VERSION ""

NS_ :

BS_:

BU_: PDCF VDC821 VDC397 HAD3971 PDCM CSC PDCR

BO_ 169 RBU_1: 32 PDCF
 SG_ Checksum_RBU_1 : 0|8@1+ (1,0) [0|255] ""  HAD3971
 SG_ RBU_WheelSpeed_FL : 8|15@1+ (0.01,0) [0|327.67] "km/h"  HAD3971
 SG_ RBU_WheelSpeed_FR : 24|15@1+ (0.01,0) [0|327.67] "km/h"  HAD3971
 SG_ RBU_WheelSpeed_RL : 40|15@1+ (0.01,0) [0|327.67] "km/h"  HAD3971
 SG_ RBU_WheelSpeed_RR : 56|15@1+ (0.01,0) [0|327.67] "km/h"  HAD3971
 SG_ RBU_ErrorSt_SBS : 72|1@1+ (1,0) [0|1] ""  HAD3971
 SG_ RBU_Intervention_SBS : 73|1@1+ (1,0) [0|1] ""  HAD3971
 SG_ RBU_EPBAvailableSt_L3 : 74|1@1+ (1,0) [0|1] ""  HAD3971
 SG_ RBU_UsedChannel_L3 : 75|2@1+ (1,0) [0|3] ""  HAD3971
 SG_ RBU_ControllerReleaseSt_L3 : 77|1@1+ (1,0) [0|1] ""  HAD3971
 SG_ RBU_SuspendStatusByDriver_L3 : 78|2@1+ (1,0) [0|3] ""  HAD3971
 SG_ RBU_BrakePedalStatus_Q : 80|2@1+ (1,0) [0|3] ""  HAD3971
 SG_ RBU_BrakePedalStatus : 82|2@1+ (1,0) [0|3] ""  HAD3971
 SG_ RBU_VLCSt : 84|2@1+ (1,0) [0|3] ""  HAD3971
 SG_ RBU_VMC_Error_L3 : 88|3@1+ (1,0) [0|7] ""  HAD3971
 SG_ RBU_DrivingDirection : 91|2@1+ (1,0) [0|3] ""  HAD3971
 SG_ RBU_VehicleSpeed : 96|15@1+ (0.01,0) [0|327.67] "km/h"  HAD3971
 SG_ RBU_TargetGearReq_VMC_1 : 114|3@1+ (1,0) [0|7] ""  HAD3971
 SG_ RBU_TargetGearReqEnable_VMC_1 : 117|1@1+ (1,0) [0|1] ""  HAD3971
 SG_ RBU_VehicleStandstillSt : 118|1@1+ (1,0) [0|1] ""  HAD3971
 SG_ RBU_BrakeLightCtrlCmd : 119|1@1+ (1,0) [0|1] ""  HAD3971
 SG_ RBUIBC_DriveMain2BackupState : 120|4@1+ (1,0) [0|15] "" Vector__XXX
 SG_ RBUIBC_StopMain2BackupState : 124|4@1+ (1,0) [0|7] "" Vector__XXX
 SG_ RBUIPB_RBUSelfTestInfo : 128|4@1+ (1,0) [0|15] "" Vector__XXX
 SG_ RBUIBC_VariantInfo : 132|1@1+ (1,0) [0|1] "" Vector__XXX
 SG_ LiveCounter_RBU_1 : 252|4@1+ (1,0) [0|15] ""  HAD3971

BO_ 1382 RBU_SlaveFVReq: 8 PDCF
 SG_ SECOC_FVReqCode_RBU : 0|8@1+ (1,0) [0|0] ""  VDC397

BO_ 190 RVA_1: 16 PDCF
 SG_ Checksum_RVA_1 : 0|8@1+ (1,0) [0|255] ""  VDC397,HAD3971
 SG_ SteerRearControlAngleReq_RVA : 8|12@1+ (0.01,-20.48) [-20.48|20.47] "°„"  VDC397,HAD3971
 SG_ SteerRearControlSt_RVA : 20|2@1+ (1,0) [0|3] ""  VDC397,HAD3971
 SG_ WorkingSt_RVA : 24|3@1+ (1,0) [0|7] ""  VDC397,HAD3971
 SG_ BehaviorMode_RVA : 27|3@1+ (1,0) [0|7] ""  VDC397,HAD3971
 SG_ ErrorSt_RVA : 30|2@1+ (1,0) [0|3] ""  VDC397,HAD3971
 SG_ IBCControlAvailable_RVA : 32|1@1+ (1,0) [0|1] ""  VDC397,HAD3971
 SG_ APAControlSt_RVA : 33|1@1+ (1,0) [0|1] ""  VDC397,HAD3971
 SG_ APAAbortFeedback_RVA : 34|5@1+ (1,0) [0|31] ""  VDC397,HAD3971
 SG_ SACCControlSt_RVA : 40|2@1+ (1,0) [0|3] ""  VDC397,HAD3971
 SG_ LKAControlSt_RVA : 42|2@1+ (1,0) [0|3] ""  VDC397,HAD3971
 SG_ NOPControlSt_RVA : 44|2@1+ (1,0) [0|3] ""  VDC397,HAD3971
 SG_ Livecounter_RVA_1 : 60|4@1+ (1,0) [0|15] ""  VDC397,HAD3971
 SG_ SECOC_FV_RVA_1 : 64|16@1+ (1,0) [0|0] ""  VDC397
 SG_ SECOC_TMAC_RVA_1 : 80|48@1+ (1,0) [0|0] ""  VDC397

BO_ 188 RWS_1: 16 PDCF
 SG_ Checksum_RWS_1 : 0|8@1+ (1,0) [0|255] ""  HAD3971
 SG_ RearWheelAngle : 8|12@1+ (0.01,-20.48) [-20.48|20.47] "°„"  HAD3971
 SG_ RearWheelAngle_QF : 22|2@1+ (1,0) [0|3] ""  HAD3971
 SG_ RearWheelAngleSpeed : 24|13@1+ (0.01,-40.96) [-40.96|40.95] "°„/s"  HAD3971
 SG_ WorkingSt_RWS : 40|3@1+ (1,0) [0|7] ""  HAD3971
 SG_ ErrorSt_RWS : 43|2@1+ (1,0) [0|3] ""  HAD3971
 SG_ LiveCounter_RWS_1 : 60|4@1+ (1,0) [0|15] ""  HAD3971
 SG_ SECOC_FV_RWS_1 : 64|16@1+ (1,0) [0|0] ""  VDC397
 SG_ SECOC_TMAC_RWS_1 : 80|48@1+ (1,0) [0|0] ""  VDC397

BO_ 189 RWS_2: 8 PDCF
 SG_ MaxAngle_RWS : 8|12@1+ (0.01,-20.48) [-20.48|20.47] "°„"  HAD3971
 SG_ MaxAngleGrad_RWS : 24|13@1+ (0.01,-40.96) [-40.96|40.95] "°„/s"  HAD3971

BO_ 1383 RWS_SlaveFVReq: 8 PDCF
 SG_ SECOC_FVReqCode_RWS : 0|8@1+ (1,0) [0|0] ""  VDC397

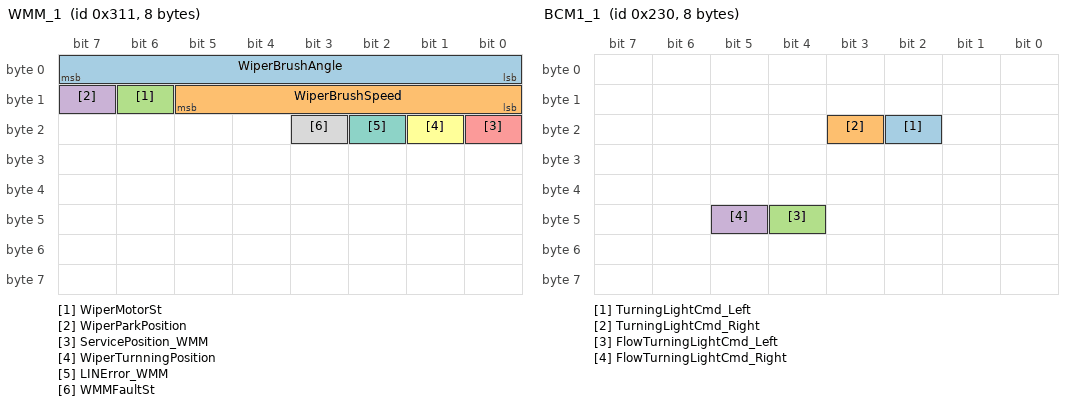
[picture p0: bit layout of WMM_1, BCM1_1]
BO_ 785 WMM_1: 8 PDCF
 SG_ WiperBrushAngle : 0|8@1+ (1,0) [0|255] "degree"  VDC821
 SG_ WiperBrushSpeed : 8|6@1+ (1,0) [0|63] "times/min"  VDC821
 SG_ WiperMotorSt : 14|1@1+ (1,0) [0|1] ""  VDC821
 SG_ WiperParkPosition : 15|1@1+ (1,0) [0|1] ""  VDC821
 SG_ ServicePosition_WMM : 16|1@1+ (1,0) [0|1] ""  VDC821
 SG_ WiperTurnningPosition : 17|1@1+ (1,0) [0|1] ""  VDC821
 SG_ LINError_WMM : 18|1@1+ (1,0) [0|1] ""  VDC821
 SG_ WMMFaultSt : 19|1@1+ (1,0) [0|1] ""  VDC821

BO_ 560 BCM1_1: 8 VDC821
 SG_ TurningLightCmd_Left : 18|1@1+ (1,0) [0|1] ""  PDCF
 SG_ TurningLightCmd_Right : 19|1@1+ (1,0) [0|1] ""  PDCF
 SG_ FlowTurningLightCmd_Left : 44|1@1+ (1,0) [0|1] ""  PDCF
 SG_ FlowTurningLightCmd_Right : 45|1@1+ (1,0) [0|1] ""  PDCF

BO_ 562 BCM1_2: 8 VDC821
 SG_ PowerMode : 4|4@1+ (1,0) [0|15] ""  PDCF

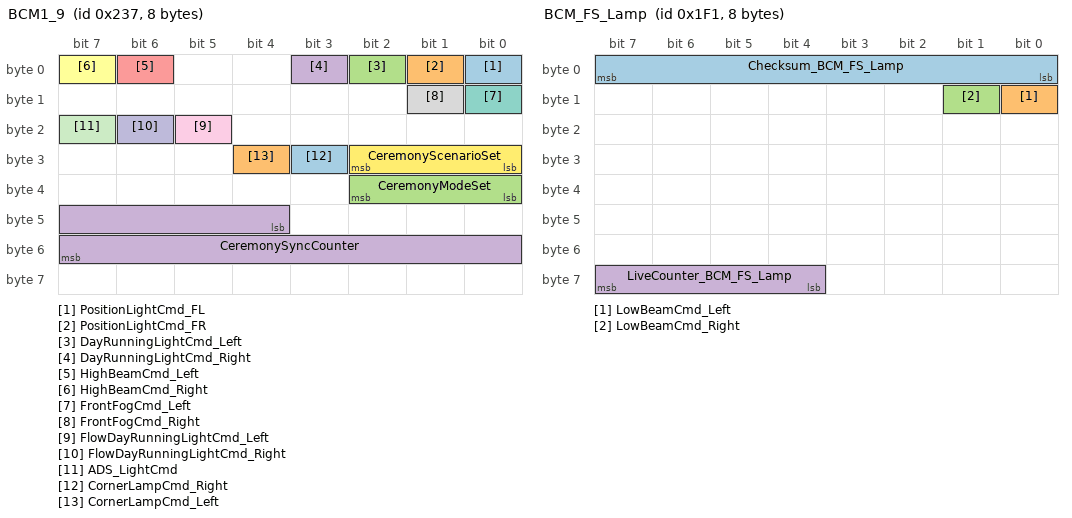
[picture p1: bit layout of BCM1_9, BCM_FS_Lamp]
BO_ 567 BCM1_9: 8 VDC821
 SG_ PositionLightCmd_FL : 0|1@1+ (1,0) [0|1] ""  PDCF
 SG_ PositionLightCmd_FR : 1|1@1+ (1,0) [0|1] ""  PDCF
 SG_ DayRunningLightCmd_Left : 2|1@1+ (1,0) [0|1] ""  PDCF
 SG_ DayRunningLightCmd_Right : 3|1@1+ (1,0) [0|1] ""  PDCF
 SG_ HighBeamCmd_Left : 6|1@1+ (1,0) [0|1] ""  PDCF
 SG_ HighBeamCmd_Right : 7|1@1+ (1,0) [0|1] ""  PDCF
 SG_ FrontFogCmd_Left : 8|1@1+ (1,0) [0|1] ""  PDCF
 SG_ FrontFogCmd_Right : 9|1@1+ (1,0) [0|1] ""  PDCF
 SG_ FlowDayRunningLightCmd_Left : 21|1@1+ (1,0) [0|1] ""  PDCF
 SG_ FlowDayRunningLightCmd_Right : 22|1@1+ (1,0) [0|1] ""  PDCF
 SG_ ADS_LightCmd : 23|1@1+ (1,0) [0|1] ""  PDCF
 SG_ CeremonyScenarioSet : 24|3@1+ (1,0) [0|7] ""  PDCF
 SG_ CornerLampCmd_Right : 27|1@1+ (1,0) [0|1] ""  PDCF
 SG_ CornerLampCmd_Left : 28|1@1+ (1,0) [0|1] ""  PDCF
 SG_ CeremonyModeSet : 32|3@1+ (1,0) [0|7] ""  PDCF
 SG_ CeremonySyncCounter : 44|12@1+ (1,0) [0|4000] ""  PDCF

BO_ 497 BCM_FS_Lamp: 8 VDC821
 SG_ Checksum_BCM_FS_Lamp : 0|8@1+ (1,0) [0|255] ""  PDCF
 SG_ LowBeamCmd_Left : 8|1@1+ (1,0) [0|1] ""  PDCF
 SG_ LowBeamCmd_Right : 9|1@1+ (1,0) [0|1] ""  PDCF
 SG_ LiveCounter_BCM_FS_Lamp : 60|4@1+ (1,0) [0|15] "pulse"  PDCF

BO_ 532 DMS_1: 8 VDC821
 SG_ DMS_ESCModeChangeCmd : 16|4@1+ (1,0) [0|15] ""  PDCF
 SG_ DMS_EPSModeChangeCmd : 20|2@1+ (1,0) [0|3] ""  PDCF

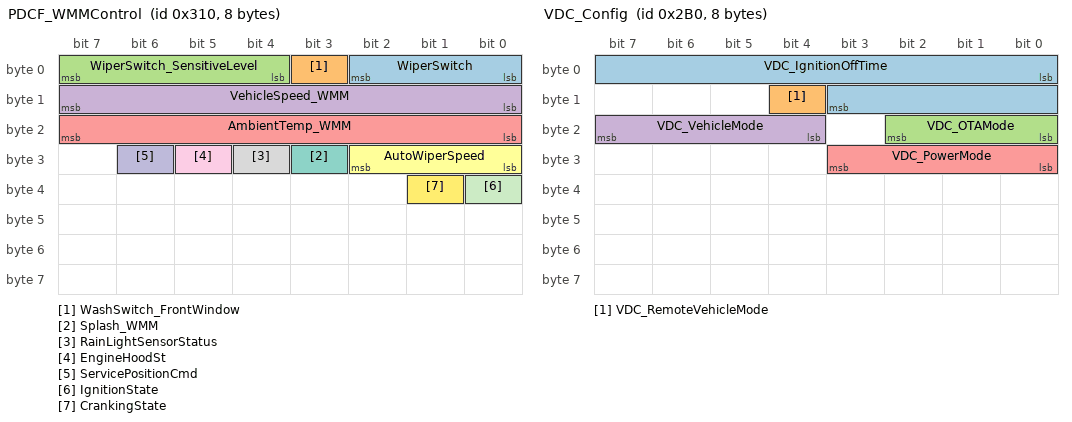
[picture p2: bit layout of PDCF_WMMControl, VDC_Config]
BO_ 784 PDCF_WMMControl: 8 VDC821
 SG_ WiperSwitch : 0|3@1+ (1,0) [0|7] ""  PDCF
 SG_ WashSwitch_FrontWindow : 3|1@1+ (1,0) [0|1] ""  PDCF
 SG_ WiperSwitch_SensitiveLevel : 4|4@1+ (1,0) [0|15] ""  PDCF
 SG_ VehicleSpeed_WMM : 8|8@1+ (2.56,0) [0|652.8] "km/h"  PDCF
 SG_ AmbientTemp_WMM : 16|8@1+ (0.5,-40) [-40|87.5] "°„C"  PDCF
 SG_ AutoWiperSpeed : 24|3@1+ (1,0) [0|7] ""  PDCF
 SG_ Splash_WMM : 27|1@1+ (1,0) [0|1] ""  PDCF
 SG_ RainLightSensorStatus : 28|1@1+ (1,0) [0|1] ""  PDCF
 SG_ EngineHoodSt : 29|1@1+ (1,0) [0|1] ""  PDCF
 SG_ ServicePositionCmd : 30|1@1+ (1,0) [0|1] ""  PDCF
 SG_ IgnitionState : 32|1@1+ (1,0) [0|1] ""  PDCF
 SG_ CrankingState : 33|1@1+ (1,0) [0|1] ""  PDCF

BO_ 890 SignLampCmd_1: 8 VDC821
 SG_ SignLamp1_Cmd : 12|1@1+ (1,0) [0|1] ""  PDCF
 SG_ SignLamp2_Cmd : 13|1@1+ (1,0) [0|1] ""  PDCF

BO_ 688 VDC_Config: 8 VDC821
 SG_ VDC_IgnitionOffTime : 0|12@1+ (1,0) [0|4095] "minute"  PDCF
 SG_ VDC_RemoteVehicleMode : 12|1@1+ (1,0) [0|1] ""  PDCF
 SG_ VDC_OTAMode : 16|3@1+ (1,0) [0|7] ""  PDCF
 SG_ VDC_VehicleMode : 20|4@1+ (1,0) [0|15] ""  PDCF
 SG_ VDC_PowerMode : 24|4@1+ (1,0) [0|15] ""  PDCF

BO_ 256 ADV_2: 32 VDC397
 SG_ Checksum_ADV_2 : 0|8@1+ (1,0) [0|255] ""  PDCF
 SG_ ADV_ErrorSt_EPS : 8|1@1+ (1,0) [0|1] ""  PDCF
 SG_ ADV_AutoParkingModeReq : 9|3@1+ (1,0) [0|7] ""  PDCF
 SG_ ADV_AutoParkingRequestSt : 12|2@1+ (1,0) [0|3] ""  PDCF
 SG_ APA_DriverInterventionSt : 15|1@1+ (1,0) [0|1] ""  PDCF
 SG_ ADV_ErrorSt_APA : 16|2@1+ (1,0) [0|3] ""  PDCF
 SG_ ADV_ErrorSt_RPA : 18|2@1+ (1,0) [0|3] ""  PDCF
 SG_ ADV_ErrorSt_AVP : 20|2@1+ (1,0) [0|3] ""  PDCF
 SG_ ADV_ErrorSt_RVA : 22|2@1+ (1,0) [0|3] ""  PDCF
 SG_ ADV_WorkingSt_APA : 24|3@1+ (1,0) [0|7] ""  PDCF
 SG_ ADV_WorkingSt_RPA : 27|3@1+ (1,0) [0|7] ""  PDCF
 SG_ ADV_WorkingSt_AVP : 32|3@1+ (1,0) [0|7] ""  PDCF
 SG_ APA_SecureRequest : 35|1@1+ (1,0) [0|1] ""  PDCF
 SG_ APA_AutoParkingReq : 36|1@1+ (1,0) [0|1] ""  PDCF
 SG_ APA_DirectionCmd : 37|2@1+ (1,0) [0|3] ""  PDCF
 SG_ ADV_SteeringWheelAngleRequest : 40|15@1+ (0.04375,0) [0|1433.55625] "°„"  PDCF
 SG_ ADV_SteeringWheelAngleSignReques : 56|2@1+ (1,0) [0|3] ""  PDCF
 SG_ ADV_SteeringWheelAngleControlReq : 58|2@1+ (1,0) [0|3] ""  PDCF
 SG_ ADV_RearWheelAngleRequestSt : 62|2@1+ (1,0) [0|3] ""  PDCF
 SG_ ADV_RearWheelAngleRequest : 64|12@1+ (0.01,-20.48) [-20.48|20.47] "°„"  PDCF
 SG_ APA_BrakeFunctionMode : 76|4@1+ (1,0) [0|15] ""  PDCF
 SG_ APA_StopDistance : 80|12@1+ (1,0) [0|4095] "cm"  PDCF
 SG_ APA_SpeedLimitation : 96|8@1+ (0.1,0) [0|15] "km/h"  PDCF
 SG_ APA_FailureBrakeMode : 104|3@1+ (1,0) [0|7] ""  PDCF
 SG_ APA_EPBLockedRequest : 107|1@1+ (1,0) [0|1] ""  PDCF
 SG_ APA_EPBRequestEnable : 108|1@1+ (1,0) [0|1] ""  PDCF
 SG_ LiveCounter_ADV_2 : 188|4@1+ (1,0) [0|15] "Pulse"  PDCF
 SG_ SECOC_FV_ADV_2 : 192|16@1+ (1,0) [0|0] ""  PDCF
 SG_ SECOC_TMAC_ADV_2 : 208|48@1+ (1,0) [0|0] ""  PDCF

BO_ 151 HCU_2_10: 32 VDC397
 SG_ Checksum_HCU_2_10 : 0|8@1+ (1,0) [0|255] ""  PDCF
 SG_ HCU_MCU1TMSpeed : 8|16@1+ (1,-30000) [-30000|30000] "rpm"  PDCF
 SG_ HCU_FrontWheelActTorque : 24|14@1+ (1,-8000) [-8000|8000] "Nm"  PDCF
 SG_ HCU_FrontWheelActTorqueSt : 39|1@1+ (1,0) [0|1] ""  PDCF
 SG_ HCU_FrontWheelMaxDriveTorque : 40|13@1+ (1,0) [0|8000] "Nm"  PDCF
 SG_ HCU_FrontWheelMaxDriveTorqueSt : 55|1@1+ (1,0) [0|1] ""  PDCF
 SG_ HCU_FrontWheelMaxBrakeRegTorque : 56|13@1+ (1,-8000) [-8000|0] "Nm"  PDCF
 SG_ HCU_FrontWheelMaxBrakeRegTorqSt : 71|1@1+ (1,0) [0|1] ""  PDCF
 SG_ HCU_FrontWheelBrakeRegTorque : 72|13@1+ (1,-8000) [-8000|0] "Nm"  PDCF
 SG_ HCU_FrontWheelBrakeRegTorqueSt : 87|1@1+ (1,0) [0|1] ""  PDCF
 SG_ HCU_MCU2TMSpeed : 88|16@1+ (1,-30000) [-30000|30000] "rpm"  PDCF
 SG_ HCU_RearWheelActTorque : 104|14@1+ (1,-8000) [-8000|8000] "Nm"  PDCF
 SG_ HCU_RearWheelActTorqueSt : 119|1@1+ (1,0) [0|1] ""  PDCF
 SG_ HCU_RearWheelMaxDriveTorque : 120|13@1+ (1,0) [0|8000] "Nm"  PDCF
 SG_ HCU_RearWheelMaxDriveTorqueSt : 135|1@1+ (1,0) [0|1] ""  PDCF
 SG_ HCU_RearWheelMaxBrakeRegTorque : 136|13@1+ (1,-8000) [-8000|0] "Nm"  PDCF
 SG_ HCU_RearWheelMaxBrakeRegTorqSt : 151|1@1+ (1,0) [0|1] ""  PDCF
 SG_ HCU_RearWheelBrakeRegTorque : 152|13@1+ (1,-8000) [-8000|0] "Nm"  PDCF
 SG_ HCU_RearWheelBrakeRegTorqueSt : 167|1@1+ (1,0) [0|1] ""  PDCF
 SG_ LiveCounter_HCU_2_10 : 252|4@1+ (1,0) [0|15] "Pulse"  PDCF

BO_ 290 HCU_2_12: 16 VDC397
 SG_ Checksum_HCU_2_12 : 0|8@1+ (1,0) [0|255] ""  PDCF
 SG_ HCU2_LeverInfo : 8|3@1+ (1,0) [0|7] ""  PDCF
 SG_ HCU_HighVoltageStatus : 11|1@1+ (1,0) [0|1] ""  PDCF
 SG_ HCU_AutoParkingResponse_HPA : 30|1@1+ (1,0) [0|1] ""  PDCF
 SG_ HCU_AutoParkingResponse_AVP : 31|1@1+ (1,0) [0|1] ""  PDCF
 SG_ HCU_AutoParkingResponse_APA : 32|1@1+ (1,0) [0|1] ""  PDCF
 SG_ HCU_AutoParkingResponse_RPA : 33|1@1+ (1,0) [0|1] ""  PDCF
 SG_ HCU_CapabilitySt_AutoParking : 34|2@1+ (1,0) [0|3] ""  PDCF
 SG_ HCU_PowertrainErrorSt : 40|1@1+ (1,0) [0|1] ""  PDCF
 SG_ HCU_PowertrainWorkSt : 41|3@1+ (1,0) [0|7] ""  PDCF
 SG_ HCU_MCU1TorqueCtrlAvailableSt : 44|1@1+ (1,0) [0|1] ""  PDCF
 SG_ HCU_MCU2TorqueCtrlAvailableSt : 46|1@1+ (1,0) [0|1] ""  PDCF
 SG_ Livecounter_HCU_2_12 : 60|4@1+ (1,0) [0|15] "pulse"  PDCF

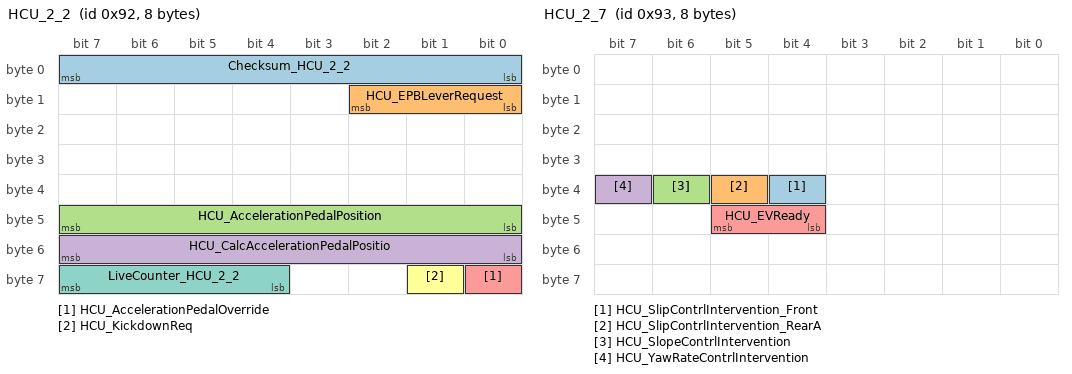
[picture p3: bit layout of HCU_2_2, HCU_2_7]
BO_ 146 HCU_2_2: 8 VDC397
 SG_ Checksum_HCU_2_2 : 0|8@1+ (1,0) [0|255] ""  PDCF
 SG_ HCU_EPBLeverRequest : 8|3@1+ (1,0) [0|7] ""  PDCF
 SG_ HCU_AccelerationPedalPosition : 40|8@1+ (0.4,0) [0|100] "%"  PDCF
 SG_ HCU_CalcAccelerationPedalPositio : 48|8@1+ (0.4,0) [0|100] "%"  PDCF
 SG_ HCU_AccelerationPedalOverride : 56|1@1+ (1,0) [0|1] ""  PDCF
 SG_ HCU_KickdownReq : 57|1@1+ (1,0) [0|1] ""  PDCF
 SG_ LiveCounter_HCU_2_2 : 60|4@1+ (1,0) [0|15] ""  PDCF

BO_ 264 HCU_2_4: 24 VDC397
 SG_ Checksum_HCU_2_4 : 0|8@1+ (1,0) [0|255] ""  PDCF
 SG_ HCU_DriverTorq_FrontWheel : 8|16@1+ (1,-3000) [-3000|13000] "Nm"  PDCF
 SG_ HCU_AutoDrivingResponseSt_L12 : 24|1@1+ (1,0) [0|1] ""  PDCF
 SG_ HCU_AutoDrivingResponseSt_L3 : 25|1@1+ (1,0) [0|1] ""  PDCF
 SG_ HCU_CruiseControlSt : 26|2@1+ (1,0) [0|3] ""  PDCF
 SG_ HCU_CapabilitySt_AutoDriving : 28|2@1+ (1,0) [0|3] ""  PDCF
 SG_ HCU_DriverTorq_RearWheel : 32|16@1+ (1,-3000) [-3000|13000] "Nm"  PDCF
 SG_ HCU_GradientAccelerationPedal : 48|8@1+ (2,-253) [-253|257] "%/s"  PDCF
 SG_ LiveCounter_HCU_2_4 : 124|4@1+ (1,0) [0|15] ""  PDCF

BO_ 147 HCU_2_7: 8 VDC397
 SG_ HCU_SlipContrlIntervention_Front : 36|1@1+ (1,0) [0|1] ""  PDCF
 SG_ HCU_SlipContrlIntervention_RearA : 37|1@1+ (1,0) [0|1] ""  PDCF
 SG_ HCU_SlopeContrlIntervention : 38|1@1+ (1,0) [0|1] ""  PDCF
 SG_ HCU_YawRateContrlIntervention : 39|1@1+ (1,0) [0|1] ""  PDCF
 SG_ HCU_EVReady : 44|2@1+ (1,0) [0|3] ""  PDCF

BO_ 1376 VDC397_MasterFVM: 16 VDC397
 SG_ SECOC_TripCounter : 0|24@1+ (1,0) [0|0] ""  PDCF
 SG_ SECOC_ResetCounter : 24|16@1+ (1,0) [0|0] ""  PDCF
 SG_ SECOC_Authenticator : 40|88@1+ (1,0) [0|0] ""  PDCF

BO_ 280 VDC_1: 32 VDC397
 SG_ Checksum_VDC_1 : 0|8@1+ (1,0) [0|255] ""  PDCF
 SG_ VDC_AutoDrivingReq_L12 : 8|2@1+ (1,0) [0|3] ""  PDCF
 SG_ VDC_DecelerationReqEnable_AEB : 10|2@1+ (1,0) [0|3] ""  PDCF
 SG_ VDC_SteeringTorqueRequestSign : 12|1@1+ (1,0) [0|1] ""  PDCF
 SG_ VDC_SteeringTorqueReqSt : 13|1@1+ (1,0) [0|1] ""  PDCF
 SG_ VDC_Intervention_LKA : 14|2@1+ (1,0) [0|3] ""  PDCF
 SG_ VDC_WorkingSt_LKA : 16|2@1+ (1,0) [0|3] ""  PDCF
 SG_ VDC_ErrorSt_LKA : 18|1@1+ (1,0) [0|1] ""  PDCF
 SG_ VDC_AccelerationPedalOverride : 19|1@1+ (1,0) [0|1] ""  PDCF
 SG_ VDC_WorkingSt_AEB_L12 : 20|2@1+ (1,0) [0|3] ""  PDCF
 SG_ VDC_ErrorSt_AEB_L12 : 22|1@1+ (1,0) [0|1] ""  PDCF
 SG_ VDC_ErrorSt_ACC_L12 : 23|1@1+ (1,0) [0|1] ""  PDCF
 SG_ VDC_SpeedChangeRequest_L12 : 24|11@1+ (0.01,-10.21) [-10.21|10.21] "m/s2"  PDCF
 SG_ VDC_DriveAwayReq_L12 : 35|1@1+ (1,0) [0|1] ""  PDCF
 SG_ VDC_StopReq_L12 : 36|1@1+ (1,0) [0|1] ""  PDCF
 SG_ VDC_WorkingSt_ACC_L12 : 37|3@1+ (1,0) [0|7] ""  PDCF
 SG_ VDC_TakeOverTip_LCA : 40|1@1+ (1,0) [0|1] ""  PDCF
 SG_ VDC_ABPReq_L12 : 41|1@1+ (1,0) [0|1] ""  PDCF
 SG_ VDC_AWBReq_L12 : 42|1@1+ (1,0) [0|1] ""  PDCF
 SG_ VDC_AWBlevel_L12 : 43|3@1+ (1,0) [0|7] ""  PDCF
 SG_ VDC_CruiseModeFunctionInd : 46|2@1+ (1,0) [0|3] ""  PDCF
 SG_ VDC_BrakeModeReq_L12 : 48|2@1+ (1,0) [0|3] ""  PDCF
 SG_ VDC_DrivedownModeReq_L12 : 50|2@1+ (1,0) [0|3] ""  PDCF
 SG_ VDC_SecureRequest_L12 : 52|1@1+ (1,0) [0|1] ""  PDCF
 SG_ VDC_AEBSensitivity_L12 : 53|2@1+ (1,0) [0|3] ""  PDCF
 SG_ VDC_ErrorSt_LCA : 55|1@1+ (1,0) [0|1] ""  PDCF
 SG_ VDC_AutoDrivingReq : 56|2@1+ (1,0) [0|3] ""  PDCF
 SG_ VDC_AutoDrivingLevel : 58|2@1+ (1,0) [0|3] ""  PDCF
 SG_ VDC_HandsOffTip_LCA : 60|2@1+ (1,0) [0|3] ""  PDCF
 SG_ VDC_ErrorSt_SACC : 62|2@1+ (1,0) [0|3] ""  PDCF
 SG_ VDC_DecelerationReq_AEB : 64|10@1+ (0.01,-10.21) [-10.21|0.2] "m/s2"  PDCF
 SG_ VDC_WorkingSt_LCA : 75|3@1+ (1,0) [0|7] ""  PDCF
 SG_ VDC_ErrorSt_VDC : 79|1@1+ (1,0) [0|1] ""  PDCF
 SG_ VDC_SteeringTorqueRequest : 80|10@1+ (0.01,0) [0|10] "Nm"  PDCF
 SG_ VDC_AutoDrivingModeReq : 90|3@1+ (1,0) [0|7] ""  PDCF
 SG_ VDC_WorkingSt_SACC : 93|3@1+ (1,0) [0|7] ""  PDCF
 SG_ VDC_WorkingSt_DCLC : 96|3@1+ (1,0) [0|7] ""  PDCF
 SG_ VDC_ErrorSt_EMA : 100|1@1+ (1,0) [0|1] ""  PDCF
 SG_ VDC_WorkingSt_EMA : 101|3@1+ (1,0) [0|7] ""  PDCF
 SG_ VDC_SteeringWheelAngleRequest : 104|15@1+ (0.04375,0) [0|1433.55625] "°„"  PDCF
 SG_ SACC_RearWheelAngleRequestSt : 119|1@1+ (1,0) [0|1] ""  PDCF
 SG_ VDC_SteeringWheelAngleSignReques : 120|2@1+ (1,0) [0|3] ""  PDCF
 SG_ VDC_SteeringWheelAngleControlReq : 122|2@1+ (1,0) [0|3] ""  PDCF
 SG_ SACC_RearWheelReturnReq : 124|1@1+ (1,0) [0|1] ""  PDCF
 SG_ LKA_RearWheelAngleRequestSt : 125|1@1+ (1,0) [0|1] ""  PDCF
 SG_ LKA_RearWheelReturnReq : 126|1@1+ (1,0) [0|1] ""  PDCF
 SG_ VDC_AutoDrivingModeReq_EMA : 127|1@1+ (1,0) [0|1] ""  PDCF
 SG_ VDC_SteeringWheelBlendingGain : 128|8@1+ (1,0) [0|100] "%"  PDCF
 SG_ VDC_SteeringMaxTorqueRequest : 136|10@1+ (0.01,0) [0|10.23] "Nm"  PDCF
 SG_ SACC_RearWheelAngleRequest : 152|12@1+ (0.01,-20.48) [-20.48|20.47] "°„"  PDCF
 SG_ LKA_RearWheelAngleRequest : 168|12@1+ (0.01,-20.48) [-20.48|20.47] "°„"  PDCF
 SG_ VDC_WorkingSt_FCW : 180|2@1+ (1,0) [0|3] ""  PDCF
 SG_ VDC_ErrorSt_FCW : 182|1@1+ (1,0) [0|1] ""  PDCF
 SG_ LiveCounter_VDC_1 : 188|4@1+ (1,0) [0|15] ""  PDCF

BO_ 282 HAD_3: 32 HAD3971
 SG_ Checksum_HAD_3 : 0|8@1+ (1,0) [0|255] ""  PDCF
 SG_ HAD_AutoDrivingReq_L3 : 8|2@1+ (1,0) [0|3] ""  PDCF
 SG_ HAD_SpeedChangeRequest_L3 : 10|11@1+ (0.01,-10.21) [-10.21|10.21] "m/s2"  PDCF
 SG_ HAD_TimeGapSetting : 21|3@1+ (1,0) [0|7] ""  PDCF
 SG_ NOP_RearWheelAngleRequest : 24|12@1+ (0.01,-20.48) [-20.48|20.47] "°„"  PDCF
 SG_ NOP_RearWheelAngleRequestSt : 36|1@1+ (1,0) [0|1] ""  PDCF
 SG_ NOP_RearWheelReturnReq : 37|1@1+ (1,0) [0|1] ""  PDCF
 SG_ HAD_ObjectDetection : 38|1@1+ (1,0) [0|1] ""  PDCF
 SG_ HAD_TakeOverReq : 39|1@1+ (1,0) [0|1] ""  PDCF
 SG_ HAD_CruiseSpeedSetting_ACC : 40|8@1+ (1,0) [0|255] "km/h"  PDCF
 SG_ HAD_SysTextinfo : 48|4@1+ (1,0) [0|15] ""  PDCF
 SG_ HAD_LDWModeInd : 52|2@1+ (1,0) [0|3] ""  PDCF
 SG_ HAD_AutoLightModeReq : 54|1@1+ (1,0) [0|1] ""  PDCF
 SG_ HAD_HazardWarningLampRequest : 55|1@1+ (1,0) [0|1] ""  PDCF
 SG_ HAD_WorkingSt_LDW : 56|2@1+ (1,0) [0|3] ""  PDCF
 SG_ HAD_WarningCmd_LDW : 58|2@1+ (1,0) [0|3] ""  PDCF
 SG_ HAD_LDWLaneDetectSt : 64|2@1+ (1,0) [0|3] ""  PDCF
 SG_ HAD_SensitivityInd_LDW : 66|2@1+ (1,0) [0|3] ""  PDCF
 SG_ HAD_ErrorSt_LDW : 68|1@1+ (1,0) [0|1] ""  PDCF
 SG_ HAD_WorkingSt_FCW : 69|2@1+ (1,0) [0|3] ""  PDCF
 SG_ HAD_DriveAwayReq_L3 : 71|1@1+ (1,0) [0|1] ""  PDCF
 SG_ HAD_StopReq_L3 : 72|1@1+ (1,0) [0|1] ""  PDCF
 SG_ HAD_AccelerationPedalOverride : 73|1@1+ (1,0) [0|1] ""  PDCF
 SG_ HAD_SensitivityInd_FCW : 74|2@1+ (1,0) [0|3] ""  PDCF
 SG_ HAD_FCWModeInd : 76|2@1+ (1,0) [0|3] ""  PDCF
 SG_ HAD_WiperAutoLeverReq : 78|1@1+ (1,0) [0|1] ""  PDCF
 SG_ HAD_VASFunctionInd : 79|1@1+ (1,0) [0|1] ""  PDCF
 SG_ HAD_SACCNotSatisfiedCondition : 80|3@1+ (1,0) [0|7] ""  PDCF
 SG_ HAD_LDW_SpeechControlFeedback : 83|3@1+ (1,0) [0|7] ""  PDCF
 SG_ HAD_IFCSystemError : 86|2@1+ (1,0) [0|3] ""  PDCF
 SG_ HAD_IFCCalibrationStatus : 88|2@1+ (1,0) [0|3] ""  PDCF
 SG_ HAD_WarningCmd_VAS : 90|1@1+ (1,0) [0|1] ""  PDCF
 SG_ HAD_LeftTurningLampRequest : 91|2@1+ (1,0) [0|3] ""  PDCF
 SG_ HAD_RightTurningLampRequest : 93|2@1+ (1,0) [0|3] ""  PDCF
 SG_ HAD_ValetModeStatus : 95|1@1+ (1,0) [0|1] ""  PDCF
 SG_ HAD_BrakeModeReq_L3 : 96|2@1+ (1,0) [0|3] ""  PDCF
 SG_ HAD_DrivedownModeReq_L3 : 98|2@1+ (1,0) [0|3] ""  PDCF
 SG_ HAD_SecureRequest_L3 : 100|2@1+ (1,0) [0|3] ""  PDCF
 SG_ HAD_ErrorSt_AutoDriving_L3 : 102|1@1+ (1,0) [0|1] ""  PDCF
 SG_ HAD_WorkingSt_NOP : 104|3@1+ (1,0) [0|7] ""  PDCF
 SG_ HAD_ErrorSt_NOP : 107|2@1+ (1,0) [0|3] ""  PDCF
 SG_ HAD_ErrorSt_HAD : 109|1@1+ (1,0) [0|1] ""  PDCF
 SG_ HAD_AutoDrivingModeReq_NOP : 110|1@1+ (1,0) [0|1] ""  PDCF
 SG_ HAD_AutoDrivingModeReq_NGP : 111|1@1+ (1,0) [0|1] ""  PDCF
 SG_ HAD_SteeringWheelBlendingGain : 112|8@1+ (1,0) [0|100] "%"  PDCF
 SG_ HAD_SteeringWheelAngleRequest : 120|15@1+ (0.04375,0) [0|1433.55625] "°„"  PDCF
 SG_ HAD_SteeringWheelAngleSignReques : 136|2@1+ (1,0) [0|3] ""  PDCF
 SG_ HAD_SteeringWheelAngleControlReq : 138|2@1+ (1,0) [0|3] ""  PDCF
 SG_ HAD_WorkingSt_NGP : 144|3@1+ (1,0) [0|7] ""  PDCF
 SG_ HAD_ErrorSt_NGP : 147|2@1+ (1,0) [0|3] ""  PDCF
 SG_ LiveCounter_HAD_3 : 188|4@1+ (1,0) [0|15] ""  PDCF

BO_ 512 ACU_1: 8 PDCM
 SG_ CrashInfo : 8|1@1+ (1,0) [0|1] ""  PDCF
 SG_ SysSt_ACU : 16|2@1+ (1,0) [0|3] ""  PDCF

BO_ 586 DDCU_1: 8 PDCM
 SG_ DoorSt_FL : 2|1@1+ (1,0) [0|1] ""  PDCF

BO_ 580 DSCU_1: 8 PDCM
 SG_ SeatBeltSt_DSCU : 28|2@1+ (1,0) [0|3] ""  PDCF

BO_ 288 EGSM_1: 8 PDCM
 SG_ EGSM_ParkButton : 8|1@1+ (1,0) [0|1] ""  PDCF

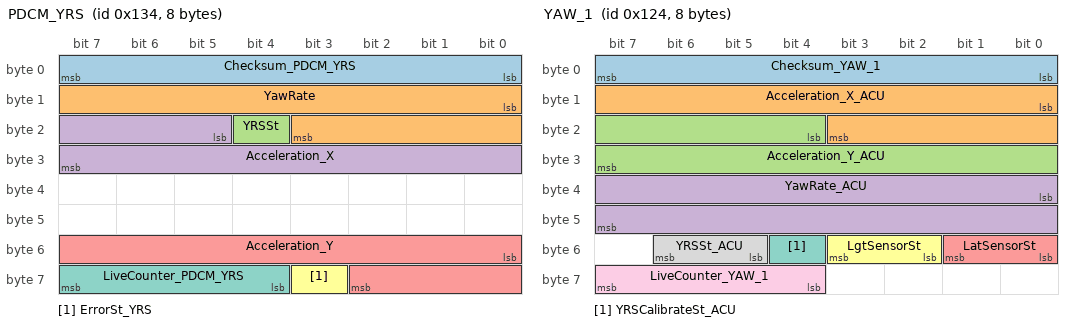
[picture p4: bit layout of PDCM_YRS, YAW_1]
BO_ 308 PDCM_YRS: 8 PDCM
 SG_ Checksum_PDCM_YRS : 0|8@1+ (1,0) [0|255] ""  PDCF
 SG_ YawRate : 8|12@1+ (0.05,-100) [-100|100] "deg/s"  PDCF
 SG_ YRSSt : 20|1@1+ (1,0) [0|1] ""  PDCF
 SG_ Acceleration_X : 21|11@1+ (0.027127,-21.593) [-21.593|21.593184] "m/s2"  PDCF
 SG_ Acceleration_Y : 48|11@1+ (0.027127,-21.593) [-21.593|21.593184] "m/s2"  PDCF
 SG_ ErrorSt_YRS : 59|1@1+ (1,0) [0|1] ""  PDCF
 SG_ LiveCounter_PDCM_YRS : 60|4@1+ (1,0) [0|15] ""  PDCF

BO_ 588 PDCU_1: 8 PDCM
 SG_ DoorSt_FR : 2|1@1+ (1,0) [0|1] ""  PDCF

BO_ 292 YAW_1: 8 PDCM
 SG_ Checksum_YAW_1 : 0|8@1+ (1,0) [0|255] ""  PDCF
 SG_ Acceleration_X_ACU : 8|12@1+ (0.001,-2) [-2|2] "g"  PDCF
 SG_ Acceleration_Y_ACU : 20|12@1+ (0.001,-2) [-2|2] "g"  PDCF
 SG_ YawRate_ACU : 32|16@1+ (0.01,-180) [-180|180] "deg/s"  PDCF
 SG_ LatSensorSt : 48|2@1+ (1,0) [0|3] ""  PDCF
 SG_ LgtSensorSt : 50|2@1+ (1,0) [0|3] ""  PDCF
 SG_ YRSCalibrateSt_ACU : 52|1@1+ (1,0) [0|1] ""  PDCF
 SG_ YRSSt_ACU : 53|2@1+ (1,0) [0|3] ""  PDCF
 SG_ LiveCounter_YAW_1 : 60|4@1+ (1,0) [0|15] ""  PDCF

BO_ 640 HU_1: 8 CSC
 SG_ EPBFunctionSet : 28|2@1+ (1,0) [0|3] ""  PDCF

CM_ SG_ 169 Checksum_RBU_1 "The checksum is used to check whether the data from the CPU buffer are shifted without transmission errors to the CAN communication controller buffer and vice versa.";
CM_ SG_ 169 RBU_WheelSpeed_FL "This signal is front left wheel speed which sent by ABS with filtering. ";
CM_ SG_ 169 RBU_WheelSpeed_FR "This signal is front right wheel speed which sent by ABS with filtering.";
CM_ SG_ 169 RBU_WheelSpeed_RL "This signal is rear left wheel speed which sent by ABS with filtering.";
CM_ SG_ 169 RBU_WheelSpeed_RR "This signal is rear right wheel speed which sent by ABS with filtering.";
CM_ SG_ 169 RBU_ErrorSt_SBS "This signal indicates the SBS function error status.";
CM_ SG_ 169 RBU_Intervention_SBS "The signal indicates if the SBS function is intervention or not.";
CM_ SG_ 169 RBU_EPBAvailableSt_L3 "This signal indicates EPB communication is available or not by RBU";
CM_ SG_ 169 RBU_UsedChannel_L3 "This signal indicates RBU feedback which communication channel is used for L3 control.";
CM_ SG_ 169 RBU_ControllerReleaseSt_L3 "This signal indicates RBU is available for L3 autodriving function or not.Release means RBU is available for L3 Control£¨Notrelease means RBU is not available for L3 Control.";
CM_ SG_ 169 RBU_SuspendStatusByDriver_L3 "This signal indicates if the RBU system is suspend during L3 Function(Driver)";
CM_ SG_ 169 RBU_BrakePedalStatus_Q "This signal is the qualifier of brake pedal status.";
CM_ SG_ 169 RBU_BrakePedalStatus "This signal is the brake pedal status.";
CM_ SG_ 169 RBU_VLCSt "This signal indicates the vehicle longitudinal control status for L123 autodriving function.";
CM_ SG_ 169 RBU_VMC_Error_L3 "This signal indicates RBU system in RBU is available for L3 autodriving function or not.";
CM_ SG_ 169 RBU_DrivingDirection "The signal indicates driving direction of the vehicle.";
CM_ SG_ 169 RBU_VehicleSpeed "The signal describes the raw vehicle speed calculated by ABS. The ABS calculates the vehicle speed based on the raw wheel speed signals from the wheel speed sensors. The vehicle speed output could be the average of the wheel speeds of the driven axle.";
CM_ SG_ 169 RBU_TargetGearReq_VMC_1 "RBU request to change the lever  position.";
CM_ SG_ 169 RBU_TargetGearReqEnable_VMC_1 "This signal is enable flag for gear request of ADAS Control by RBU";
CM_ SG_ 169 RBU_VehicleStandstillSt "The signal indicates the vehicle whether is in standstill or not by RBU";
CM_ SG_ 169 RBU_BrakeLightCtrlCmd "The signal indicates the brake light control command of RBU";
CM_ SG_ 169 RBUIBC_DriveMain2BackupState "State of the backup actuator for automated driving with brake redundancy";
CM_ SG_ 169 RBUIBC_StopMain2BackupState "State of the backup actuator for automated parking with brake redundancy";
CM_ SG_ 169 RBUIPB_RBUSelfTestInfo "IBC RBU coordination info for RBU BAT test";
CM_ SG_ 169 RBUIBC_VariantInfo "Variant Information of RBU";
CM_ SG_ 169 LiveCounter_RBU_1 "The Livecounter is used to check the signal consistency of the messages . If the signals are consecutive, the LiveCounter should also be sequential in the way 0, 1, 2 ...X(depends on E2E usage), 0, 1 °≠";
CM_ SG_ 1382 SECOC_FVReqCode_RBU "FV  request code. The signal shall be procceded following the byte order requirement in FAW-CYS-0033, i.e. SECOC spec";
CM_ SG_ 190 Checksum_RVA_1 "The checksum is used to check whether the data from the CPU buffer are shifted without transmission errors to the CAN communication controller buffer and vice versa.";
CM_ SG_ 190 SteerRearControlAngleReq_RVA "Target angle request from Master Controller";
CM_ SG_ 190 SteerRearControlSt_RVA "Control status for angle request, corporate with steer angle request to realize rear axle angle control";
CM_ SG_ 190 WorkingSt_RVA "This signal indicates the working status of RVA";
CM_ SG_ 190 BehaviorMode_RVA "This signal indicates the behavior mode of RVA";
CM_ SG_ 190 ErrorSt_RVA "This signal indicates the error status of RVA";
CM_ SG_ 190 IBCControlAvailable_RVA "Indicates IBC Control RWS is available or not.";
CM_ SG_ 190 APAControlSt_RVA "Indicates APA Control Request Feedback";
CM_ SG_ 190 APAAbortFeedback_RVA "This signal indicates APA Abort Feedback";
CM_ SG_ 190 SACCControlSt_RVA "This signal indicates the status of SACC Control SteerRearAngle";
CM_ SG_ 190 LKAControlSt_RVA "This signal indicates the status of LKA Control SteerRearAngle";
CM_ SG_ 190 NOPControlSt_RVA "This signal indicates the status of NOP Control SteerRearAngle";
CM_ SG_ 190 Livecounter_RVA_1 "The Livecounter is used to check the signal consistency of the messages . If the signals are consecutive, the LiveCounter should also be sequential in the way 0, 1, 2 °≠X(depends on E2E usage), 0, 1 °≠";
CM_ SG_ 190 SECOC_FV_RVA_1 "Fresh value signal for SECOC. The signal shall be proceeded following the byte order requirement in FAW-CYS-0033, i.e. SECOC spec";
CM_ SG_ 190 SECOC_TMAC_RVA_1 "Truncated MAC signal for SECOC. The signal shall be proceeded following the byte order requirement in FAW-CYS-0033, i.e. SECOC spec";
CM_ SG_ 188 Checksum_RWS_1 "The checksum is used to check whether the data from the CPU buffer are shifted without transmission errors to the CAN communication controller buffer and vice versa.";
CM_ SG_ 188 RearWheelAngle "This signal indicates the angle of rear wheel
anticlockwise=positive, clockwise=negative";
CM_ SG_ 188 RearWheelAngle_QF "This signal indicates the quality factor of rear wheel angle:
0x0 stands for inaccurate data (Invalid)
0x1 stands for temporary undefined data (initial)
0x2 stands for data accuracy not within specification (inaccurate)
0x3 stands for undefined data accuracy (Valid)";
CM_ SG_ 188 RearWheelAngleSpeed "This signal indicates the angle speed of rear wheel";
CM_ SG_ 188 WorkingSt_RWS "This signal indicates the working state of RWS:
0x0 stands for Initialisation
0x1 stands for Pending
0x2 stands for Normal
0x3 stands for Red
0x4 stands for Yellow
0x5 stands for Ramping
0x6 stands for Inactive
0x7 stands for Diagnosis";
CM_ SG_ 188 ErrorSt_RWS "This signal indicates the system error status of RWS:
0x0 stands for system no error reports
0x1 stands for Error_Yellow
0x2 stands for Error_Red
0x3 is reserved";
CM_ SG_ 188 LiveCounter_RWS_1 "The Livecounter is used to check the signal consistency of the messages . If the signals are consecutive, the LiveCounter should also be sequential in the way 0, 1, 2 °≠X(depends on E2E usage), 0, 1 °≠";
CM_ SG_ 188 SECOC_FV_RWS_1 "Fresh value signal for SECOC. The signal shall be proceeded following the byte order requirement in FAW-CYS-0033, i.e. SECOC spec";
CM_ SG_ 188 SECOC_TMAC_RWS_1 "Truncated MAC signal for SECOC. The signal shall be proceeded following the byte order requirement in FAW-CYS-0033, i.e. SECOC spec";
CM_ SG_ 189 MaxAngle_RWS "Function safety allowed max. steer angle depends on vehicle speed from RWS actuator
anticlockwise=positive, clockwise=negative";
CM_ SG_ 189 MaxAngleGrad_RWS "This signal indicates the angle speed of rear wheel";
CM_ SG_ 1383 SECOC_FVReqCode_RWS "FV  request code. The signal shall be procceded following the byte order requirement in FAW-CYS-0033, i.e. SECOC spec";
CM_ SG_ 785 WiperBrushAngle "Indicates the current angle of the wiper brush";
CM_ SG_ 785 WiperBrushSpeed "Indicates the current speed of the wiper brush";
CM_ SG_ 785 WiperMotorSt "Indicates WMM is running or not.
When the WMM is running, this signal should be set.";
CM_ SG_ 785 WiperParkPosition "Indicates the wiper brush has been in the park position.
Note: when the wiper bush is in the park position or the down turning position, this signal should be set.
";
CM_ SG_ 785 ServicePosition_WMM "This signal Indicates the wiper brush has been in the service position";
CM_ SG_ 785 WiperTurnningPosition "Indicate the wiper brush has been in the up turning postion or the down turning position.
Note: this signal is reserved for RLS, which can caculate the time that the wiper brush passes the RLS.
";
CM_ SG_ 785 LINError_WMM "The signal indicates if  WMM is in LIN error status or not.
If the LIN slave detects the response error, LIN Error signal should be set.";
CM_ SG_ 785 WMMFaultSt "This signal shows WMM (wiper controller module)  fault status. ";
CM_ SG_ 560 TurningLightCmd_Left "BCM1 control the flash frequency according to turn light error signal and turn light flash mode.";
CM_ SG_ 560 TurningLightCmd_Right "BCM1 control the flash frequency according to turn light error signal and turn light flash mode.";
CM_ SG_ 560 FlowTurningLightCmd_Left "BCM1 control the flash frequency according to turn light error signal and turn light flash mode.";
CM_ SG_ 560 FlowTurningLightCmd_Right "BCM1 control the flash frequency according to turn light error signal and turn light flash mode.";
CM_ SG_ 562 PowerMode "The signal indicates the vehicle power mode.";
CM_ SG_ 567 PositionLightCmd_FL "The signal indicates the control command of front left position light.";
CM_ SG_ 567 PositionLightCmd_FR "The signal indicates the control command of front right position light.";
CM_ SG_ 567 DayRunningLightCmd_Left "The signal indicates the control command of left day running light.";
CM_ SG_ 567 DayRunningLightCmd_Right "The signal indicates the control command of right day running light.";
CM_ SG_ 567 HighBeamCmd_Left "The signal  indicates the control command of left high beam indicator.";
CM_ SG_ 567 HighBeamCmd_Right "The signal  indicates the control command of right high beam indicator.";
CM_ SG_ 567 FrontFogCmd_Left "The signal indicates the control command of front left fog indicator.";
CM_ SG_ 567 FrontFogCmd_Right "The signal indicates the control command of front right fog indicator.";
CM_ SG_ 567 FlowDayRunningLightCmd_Left "The signal indicates the flow control command of left day running light.";
CM_ SG_ 567 FlowDayRunningLightCmd_Right "The signal indicates the flow control command of right day running light.";
CM_ SG_ 567 ADS_LightCmd "The signal indicates the ADS_LightCmd OFF/ON";
CM_ SG_ 567 CeremonyScenarioSet "The signal indicates the ceremony scenario.";
CM_ SG_ 567 CornerLampCmd_Right "The signal indicates the control command of right corner light";
CM_ SG_ 567 CornerLampCmd_Left "The signal indicates the control command of left corner light";
CM_ SG_ 567 CeremonyModeSet "This signal indicates BCM set the ceremony mode to light controller.";
CM_ SG_ 567 CeremonySyncCounter "This signal is used to sync the ceremony light controller.";
CM_ SG_ 497 Checksum_BCM_FS_Lamp "The checksum is used to check whether the data from the CPU buffer are shifted without transmission errors to the CAN communication controller buffer and vice versa.";
CM_ SG_ 497 LowBeamCmd_Left "The signal  indicates the control command of left low beam indicator.";
CM_ SG_ 497 LowBeamCmd_Right "The signal  indicates the control command of right low beam indicator.";
CM_ SG_ 497 LiveCounter_BCM_FS_Lamp "The Livecounter is used to check the signal consistency of the messages . If the signals are consecutive, the LiveCounter should also be sequential in the way 0, 1, 2 °≠15, 0, 1 °≠";
CM_ SG_ 532 DMS_ESCModeChangeCmd "The command of changing ESC working mode from Drive Mode Selection ECU.";
CM_ SG_ 532 DMS_EPSModeChangeCmd "The command of changing EPS working mode from Drive Mode Selection ECU";
CM_ SG_ 784 WiperSwitch "PDCF send the status of wiper switch to WMM.";
CM_ SG_ 784 WashSwitch_FrontWindow "PDCF send the status of window wash switch to WMM.";
CM_ SG_ 784 WiperSwitch_SensitiveLevel "PDCF send the sensitive level of the wiper switch to WMM. If entering the intermission mode, WMM should adjust the interval time according to this signal.";
CM_ SG_ 784 VehicleSpeed_WMM "This signal shows the current vehicle speed. ";
CM_ SG_ 784 AmbientTemp_WMM "the signal indicates the raw data of outside temperature sensor.";
CM_ SG_ 784 AutoWiperSpeed "This signal informs about the wiper speed requested by the RLS according to rain intensity or other factors .";
CM_ SG_ 784 Splash_WMM "This signal is set when the sensor recognizes splash (much water over the sensor suddenly). In this moment the wiper motor must change its speed to maximal speed regardless its position. That means, the wiper motor doesn°Øt wait to reach the park position to change the wipe speed.
The Splashl signal is calculated parallel to the other rain sensor operations. ";
CM_ SG_ 784 RainLightSensorStatus "RLS is error, or the RLS function is closed with operateing the button in HMI of Head unit, this signal should be set to °∞inactive°±.
If the RLS is inactive, the auto mode of wiper should change to intermission mode.";
CM_ SG_ 784 EngineHoodSt "If the engine hood is on, the wiper function should disable.";
CM_ SG_ 784 ServicePositionCmd "PDCF send the command of entering the service position to WMM. 
Note:
1.PDCF should judge the ignition stauts and wiper MIST switch instead of WMM, then inform WMM to enter the service position.
2.Operateing the button in HMI of Head unit, PDCF should also inform WMM to enter the service position.";
CM_ SG_ 784 IgnitionState "This signal is set when Klemme 15 is on. The wiper is active when the KL.15 is on(or KL.15 off with in 10 senconds,WMM can respones the signal of PDCF_ServicePositionCmd)";
CM_ SG_ 784 CrankingState "This signal is set when the engine is cranking. The wiper function should disable when the engine is cranking.";
CM_ SG_ 890 SignLamp1_Cmd "Indicates the SignLamp1_Cmd, signlap1 is flagsignlamp";
CM_ SG_ 890 SignLamp2_Cmd "Indicates the SignLamp1_Cmd, signlap2 is grillage lamp";
CM_ SG_ 688 VDC_IgnitionOffTime "Indicates the time between last KL15 off and this KL15 on. If the counter is overflow, it still sends 4093. The counter will be reset when KL15 Off";
CM_ SG_ 688 VDC_RemoteVehicleMode "The signal indicates the vehicle is in remote mode or not";
CM_ SG_ 688 VDC_OTAMode "The signal indicates the vehicle is in OTA mode or not";
CM_ SG_ 688 VDC_VehicleMode "The signal indicates the vehicle mode provided from VDC vehicle mode module.";
CM_ SG_ 688 VDC_PowerMode "The signal indicates the vehicle power mode provided from VDC power mode module.";
CM_ SG_ 256 ADV_ErrorSt_EPS "This signal indicates ADV is error or not.If the value of this signal is °∞Error°Æ,EPS shoud ignore this message and rESCond the message from ADV.";
CM_ SG_ 256 ADV_AutoParkingModeReq "Auto parking mode request";
CM_ SG_ 256 ADV_AutoParkingRequestSt "Auto Parking request status";
CM_ SG_ 256 APA_DriverInterventionSt "This signal indicates if driver inervention during APA/RPA/AVP/HPA function";
CM_ SG_ 256 ADV_ErrorSt_APA "ADV system capbility for APA";
CM_ SG_ 256 ADV_ErrorSt_RPA "ADV system capbility for RPA";
CM_ SG_ 256 ADV_ErrorSt_AVP "ADV system capbility for AVP";
CM_ SG_ 256 ADV_ErrorSt_RVA "This signal indicates ADV is error or not.If the value of this signal is °∞Error°Æ,RVA shoud ignore this message and rESCond the message from ADV.";
CM_ SG_ 256 ADV_WorkingSt_APA "This signal indicates the APA working status.";
CM_ SG_ 256 ADV_WorkingSt_RPA "This signal indicates the RPA working status.";
CM_ SG_ 256 ADV_WorkingSt_AVP "This signal indicates the AVP working status.";
CM_ SG_ 256 APA_SecureRequest "In the emergency condition,APA requests P locking and push EPB.
This signal is used for L1L2L3 function.";
CM_ SG_ 256 APA_AutoParkingReq "HAD request to active auto parking function.
";
CM_ SG_ 256 APA_DirectionCmd "The heading direction command from HAD/ADV in APA/RPA function.";
CM_ SG_ 256 ADV_SteeringWheelAngleRequest "Steering Wheel Angle Request";
CM_ SG_ 256 ADV_SteeringWheelAngleSignReques "Steering Wheel Angle Sign Request";
CM_ SG_ 256 ADV_SteeringWheelAngleControlReq "Steering Wheel Angle Control Request";
CM_ SG_ 256 ADV_RearWheelAngleRequestSt "This signal indicates the request status of  APA,AVP,RPA,HPA";
CM_ SG_ 256 ADV_RearWheelAngleRequest "This signal indicates the absolute value of APA,AVP,RPA,HPA rear wheel angle request";
CM_ SG_ 256 APA_BrakeFunctionMode "This signal indicate which function mode the ESC enters";
CM_ SG_ 256 APA_StopDistance "This signal inform the ESC the parking target distance ";
CM_ SG_ 256 APA_SpeedLimitation "This signal inform ESC the velocity maximum";
CM_ SG_ 256 APA_FailureBrakeMode "This signal indicates the brake mode when APA/RPA failure";
CM_ SG_ 256 APA_EPBLockedRequest "APC request to lock EPB.
";
CM_ SG_ 256 APA_EPBRequestEnable "This signal indicates EPB request enable status.
";
CM_ SG_ 256 SECOC_FV_ADV_2 "Fresh value signal for SECOC. The signal shall be proceeded following the byte order requirement in FAW-CYS-0033, i.e. SECOC spec";
CM_ SG_ 256 SECOC_TMAC_ADV_2 "Truncated MAC signal for SECOC. The signal shall be proceeded following the byte order requirement in FAW-CYS-0033, i.e. SECOC spec";
CM_ SG_ 151 Checksum_HCU_2_10 "The checksum is used to check whether the data from the CPU buffer are shifted without transmission errors to the CAN communication controller buffer and vice versa.";
CM_ SG_ 151 HCU_MCU1TMSpeed "The TM Speed of MCU1.Positive value means forward, negative value means backward.";
CM_ SG_ 151 HCU_FrontWheelActTorque "The torque of the power system acting on the wheel ends of the front axle";
CM_ SG_ 151 HCU_FrontWheelActTorqueSt "The torque state of the power system acting on the wheel end of the front axle";
CM_ SG_ 151 HCU_FrontWheelMaxDriveTorque "The Maximum driving torque capacity at the wheel end of the front axle";
CM_ SG_ 151 HCU_FrontWheelMaxDriveTorqueSt "The Maximum driving torque status capacity at the wheel end of the front axle";
CM_ SG_ 151 HCU_FrontWheelMaxBrakeRegTorque "The Maximum brake recovery capacity torque at the wheel end of the front axle";
CM_ SG_ 151 HCU_FrontWheelMaxBrakeRegTorqSt "The Maximum brake recovery capacity torque status at the wheel end of the front axle";
CM_ SG_ 151 HCU_FrontWheelBrakeRegTorque "Front axle wheel end braking energy recovery torque (not including coasting recovery)";
CM_ SG_ 151 HCU_FrontWheelBrakeRegTorqueSt "Front axle wheel end braking energy recovery torque state";
CM_ SG_ 151 HCU_MCU2TMSpeed "The TM Speed of MCU2";
CM_ SG_ 151 HCU_RearWheelActTorque "The torque of the power system acting on the wheel ends of the Rear axle";
CM_ SG_ 151 HCU_RearWheelActTorqueSt "The torque state of the power system acting on the wheel end of the Rear axle";
CM_ SG_ 151 HCU_RearWheelMaxDriveTorque "The Maximum driving torque capacity at the wheel end of the Rear axle";
CM_ SG_ 151 HCU_RearWheelMaxDriveTorqueSt "The Maximum driving torque status capacity at the wheel end of the Rear axle";
CM_ SG_ 151 HCU_RearWheelMaxBrakeRegTorque "The Maximum brake recovery capacity torque at the wheel end of the Rear axle";
CM_ SG_ 151 HCU_RearWheelMaxBrakeRegTorqSt "The Maximum brake recovery capacity torque status at the wheel end of the Rear axle";
CM_ SG_ 151 HCU_RearWheelBrakeRegTorque "Rear axle wheel end braking energy recovery torque (not including coasting recovery)";
CM_ SG_ 151 HCU_RearWheelBrakeRegTorqueSt "Rear axle wheel end braking energy recovery torque state";
CM_ SG_ 151 LiveCounter_HCU_2_10 "The Livecounter is used to check the signal consistency of the messages . If the signals are consecutive, the LiveCounter should also be sequential in the way 0, 1, 2 °≠X(depends on E2E usage), 0, 1 °≠";
CM_ SG_ 290 Checksum_HCU_2_12 "The checksum is used to check whether the data from the CPU buffer are shifted without transmission errors to the CAN communication controller buffer and vice versa.";
CM_ SG_ 290 HCU2_LeverInfo "This signal indicate Lever info for display";
CM_ SG_ 290 HCU_HighVoltageStatus "The vehcle high-voltage working status";
CM_ SG_ 290 HCU_AutoParkingResponse_HPA "The signal indicates if HCU can response the HPA autoparking request";
CM_ SG_ 290 HCU_AutoParkingResponse_AVP "The signal indicates if HCU can response the AVP autoparking request";
CM_ SG_ 290 HCU_AutoParkingResponse_APA "The signal indicates if HCU can response the APA autoparking request";
CM_ SG_ 290 HCU_AutoParkingResponse_RPA "The signal indicates if HCU can response the L3 autoparking request";
CM_ SG_ 290 HCU_CapabilitySt_AutoParking "The signal is the capability of HCU for auto parking functions.";
CM_ SG_ 290 HCU_PowertrainErrorSt "This signal indicates the powertrain system error status.";
CM_ SG_ 290 HCU_PowertrainWorkSt "This signal indicates the powertrain system working status.";
CM_ SG_ 290 HCU_MCU1TorqueCtrlAvailableSt "This signal indicates whether the MCU1 is available for external torque request.";
CM_ SG_ 290 HCU_MCU2TorqueCtrlAvailableSt "This signal indicates whether the MCU2 is available for external torque request.";
CM_ SG_ 290 Livecounter_HCU_2_12 "The Livecounter is used to check the signal consistency of the messages . If the signals are consecutive, the LiveCounter should also be sequential in the way 0, 1, 2 ...X(depends on E2E usage), 0, 1 °≠";
CM_ SG_ 146 Checksum_HCU_2_2 "The checksum is used to check whether the data from the CPU buffer are shifted without transmission errors to the CAN communication controller buffer and vice versa.";
CM_ SG_ 146 HCU_EPBLeverRequest "This signal is used for the EPB locking request of HCU. For those vehicles not configured with Epark, this signal will be used to inform EPB the lever transformation. Then EPB will lock or release the caliper according to the request.";
CM_ SG_ 146 HCU_AccelerationPedalPosition "This signal indicates the actual acceleration pedal position";
CM_ SG_ 146 HCU_CalcAccelerationPedalPositio "This signal indicates the calculated acceleration pedal position in cruise control mode.";
CM_ SG_ 146 HCU_AccelerationPedalOverride "This signal indicates the torque demanded by the driver is higher than the torque demanded by ACC.";
CM_ SG_ 146 HCU_KickdownReq "This signal is used to show the fast acceleration request from the driver. ";
CM_ SG_ 146 LiveCounter_HCU_2_2 "The Livecounter is used to check the signal consistency of the messages . If the signals are consecutive, the LiveCounter should also be sequential in the way 0, 1, 2 ...X(depends on E2E usage), 0, 1 °≠";
CM_ SG_ 264 Checksum_HCU_2_4 "The checksum is used to check whether the data from the CPU buffer are shifted without transmission errors to the CAN communication controller buffer and vice versa.";
CM_ SG_ 264 HCU_DriverTorq_FrontWheel "The indicated driver torque for front wheel.";
CM_ SG_ 264 HCU_AutoDrivingResponseSt_L12 "The signal indicates if HCU can response the L12 autodriving request or not.";
CM_ SG_ 264 HCU_AutoDrivingResponseSt_L3 "The signal indicates if HCU can response the L3 autodriving request or not.";
CM_ SG_ 264 HCU_CruiseControlSt "The cruise control status is controlled  according to the cruise control requests from the driver.";
CM_ SG_ 264 HCU_CapabilitySt_AutoDriving "The signal is the capability of HCU for auto driving functions.";
CM_ SG_ 264 HCU_DriverTorq_RearWheel "The indicated driver torque for rear wheel.";
CM_ SG_ 264 HCU_GradientAccelerationPedal "Gradient of the standardized acceleration pedal angle";
CM_ SG_ 264 LiveCounter_HCU_2_4 "The Livecounter is used to check the signal consistency of the messages . If the signals are consecutive, the LiveCounter should also be sequential in the way 0, 1, 2 ...X(depends on E2E usage), 0, 1 °≠";
CM_ SG_ 147 HCU_SlipContrlIntervention_Front "This signal indicates  if  HCU slip control function(front axle) is intervention or not.";
CM_ SG_ 147 HCU_SlipContrlIntervention_RearA "This signal indicates  if  HCU slip control function(rear axle) is intervention or not.";
CM_ SG_ 147 HCU_SlopeContrlIntervention "This signal indicates  if  HCU slop control function is intervention or not.";
CM_ SG_ 147 HCU_YawRateContrlIntervention "This signal indicates  if  HCU yaw rate control function is intervention or not.";
CM_ SG_ 147 HCU_EVReady "EV system can run or not";
CM_ SG_ 1376 SECOC_TripCounter "Trip counter value. The signal shall be procceded following the byte order requirement in FAW-CYS-0033, i.e. SECOC spec";
CM_ SG_ 1376 SECOC_ResetCounter "Reset counter value. The signal shall be procceded following the byte order requirement in FAW-CYS-0033, i.e. SECOC spec";
CM_ SG_ 1376 SECOC_Authenticator "CMAC value. The signal shall be procceded  following the  byte order requirement in FAW-CYS-0033, i.e. SECOC spec";
CM_ SG_ 280 Checksum_VDC_1 "The checksum is used to check whether the data from the CPU buffer are shifted without transmission errors to the CAN communication controller buffer and vice versa.";
CM_ SG_ 280 VDC_AutoDrivingReq_L12 "This signal indicates the acceleration or deceleration command is from L1L2 function £®SACC£©.
1. L12: Request assisted driving control, any related failure will deactivate the longitudinal controller.

";
CM_ SG_ 280 VDC_DecelerationReqEnable_AEB "This signal indicates the deceleration command  from AEB function.


";
CM_ SG_ 280 VDC_SteeringTorqueRequestSign "This signal Indicates sign of EMA steering torque";
CM_ SG_ 280 VDC_SteeringTorqueReqSt "This signal indicates the status of the steering torque request from EMA
";
CM_ SG_ 280 VDC_Intervention_LKA "This signal Indicates the LKA is Intervention or not";
CM_ SG_ 280 VDC_WorkingSt_LKA "This signal indicates the LKA working status.";
CM_ SG_ 280 VDC_ErrorSt_LKA "This signal indicates the LKA error status.";
CM_ SG_ 280 VDC_AccelerationPedalOverride "This signal indicates the torque demanded by the driver is higher than the torque demanded by ACC.";
CM_ SG_ 280 VDC_WorkingSt_AEB_L12 "This signal indicates the AEB working status.";
CM_ SG_ 280 VDC_ErrorSt_AEB_L12 "This signal indicates the AEB error status.";
CM_ SG_ 280 VDC_ErrorSt_ACC_L12 "This signal indicates the ACC error status.";
CM_ SG_ 280 VDC_SpeedChangeRequest_L12 "This signal is the value of acceleration request or deceleration request(SACC).";
CM_ SG_ 280 VDC_DriveAwayReq_L12 "This signal indicates VDC controller request vehicle drive off, ";
CM_ SG_ 280 VDC_StopReq_L12 "This signal indicates VDC controller request vehicle decelerate to standtill,";
CM_ SG_ 280 VDC_WorkingSt_ACC_L12 "This signal indicates the ACC working status.";
CM_ SG_ 280 VDC_TakeOverTip_LCA "This Driver should take over the vehicle.";
CM_ SG_ 280 VDC_ABPReq_L12 "This signal indicates the request for prefill function.";
CM_ SG_ 280 VDC_AWBReq_L12 "This signal in the request of the brake jerk warning to ESC.";
CM_ SG_ 280 VDC_AWBlevel_L12 "This signal indicates the different level request of the brake jerk warning.";
CM_ SG_ 280 VDC_CruiseModeFunctionInd "This signal indicates setting result of the configuration of cruise mode function.";
CM_ SG_ 280 VDC_BrakeModeReq_L12 "This signal indicate VDC request to brake cosily or urgently.
This signal is only used for L12 function";
CM_ SG_ 280 VDC_DrivedownModeReq_L12 "VDC request to quit out the auto pilot function.
This signal is only used for L12 function";
CM_ SG_ 280 VDC_SecureRequest_L12 "VDC request to stop the car safely.
This signal is only used for L12 function";
CM_ SG_ 280 VDC_AEBSensitivity_L12 "This signal indicates the sensitivity of AEB function";
CM_ SG_ 280 VDC_ErrorSt_LCA "This signal indicates the LCA error status.";
CM_ SG_ 280 VDC_AutoDrivingReq "Auto driving function active request from VDC to HCU.
";
CM_ SG_ 280 VDC_AutoDrivingLevel "This signal indicates the auto driving level of this car for auto driving data record.";
CM_ SG_ 280 VDC_HandsOffTip_LCA "Hands off, put hands on the steering wheel to active LCA function";
CM_ SG_ 280 VDC_ErrorSt_SACC "VDC system capbility for SACC";
CM_ SG_ 280 VDC_DecelerationReq_AEB "This signal is the value of  deceleration request(AEB).";
CM_ SG_ 280 VDC_WorkingSt_LCA "This signal indicates the LCA working status.";
CM_ SG_ 280 VDC_ErrorSt_VDC "This signal indicates VDC is error or not.If the value of this signal is °∞Error°Æ,EPS shoud ignore this message and respond the message from VDC.";
CM_ SG_ 280 VDC_SteeringTorqueRequest "This signal is the request steering wheel torque by EMA.in case of No Request: TorqueRequest_EMA = 0x3FE";
CM_ SG_ 280 VDC_AutoDrivingModeReq "This signal is the Source of Angle request to EPS.(LKA,SACC,L3Backup)";
CM_ SG_ 280 VDC_WorkingSt_SACC "This signal indicates the SACC working status.";
CM_ SG_ 280 VDC_WorkingSt_DCLC "This signal indicates the DCLC working status.";
CM_ SG_ 280 VDC_ErrorSt_EMA "VDC system capbility for EMA.";
CM_ SG_ 280 VDC_WorkingSt_EMA "This signal indicates the EMA working status.";
CM_ SG_ 280 VDC_SteeringWheelAngleRequest "Steering Wheel Angle Request.(LKA,SACC,NGP)";
CM_ SG_ 280 SACC_RearWheelAngleRequestSt "This signal indicates the request status of SACC";
CM_ SG_ 280 VDC_SteeringWheelAngleSignReques "Steering Wheel Angle Sign Request..(LKA,SACC,NGP)";
CM_ SG_ 280 VDC_SteeringWheelAngleControlReq "Steering Wheel Angle Control Request..(LKA,SACC,NGP)";
CM_ SG_ 280 SACC_RearWheelReturnReq "This signal indicates the return to 0 request status of SACC";
CM_ SG_ 280 LKA_RearWheelAngleRequestSt "This signal indicates the request status of LKA";
CM_ SG_ 280 LKA_RearWheelReturnReq "This signal indicates the return to 0 request status of LKA";
CM_ SG_ 280 VDC_AutoDrivingModeReq_EMA "This signal is the Source of Torque request to EPS.(EMA)";
CM_ SG_ 280 VDC_SteeringWheelBlendingGain "Blending Gain Factor";
CM_ SG_ 280 VDC_SteeringMaxTorqueRequest "This signal indicates SACC/LKA request Max steering wheel torque .in case of Override ";
CM_ SG_ 280 SACC_RearWheelAngleRequest "This signal indicates the absolute value of SACC rear wheel angle request";
CM_ SG_ 280 LKA_RearWheelAngleRequest "This signal indicates the absolute value of LKA rear wheel angle request";
CM_ SG_ 280 VDC_WorkingSt_FCW "This signal indicates the FCW system working status.";
CM_ SG_ 280 VDC_ErrorSt_FCW "This signal indicates the FCW error status.";
CM_ SG_ 280 LiveCounter_VDC_1 "The Livecounter is used to check the signal consistency of the messages . If the signals are consecutive, the LiveCounter should also be sequential in the way 0, 1, 2 ...X(depends on E2E usage), 0, 1 °≠";
CM_ SG_ 282 Checksum_HAD_3 "The checksum is used to check whether the data from the CPU buffer are shifted without transmission errors to the CAN communication controller buffer and vice versa.";
CM_ SG_ 282 HAD_AutoDrivingReq_L3 "This signal indicates the acceleration or deceleration command is from L1L2 function or L3 function.";
CM_ SG_ 282 HAD_SpeedChangeRequest_L3 "This signal is the value of acceleration request or deceleration request(L3).";
CM_ SG_ 282 HAD_TimeGapSetting "The cruise time gap  is setted according to the control requests from the driver.";
CM_ SG_ 282 NOP_RearWheelAngleRequest "This signal indicates the absolute value of NOP rear wheel angle request";
CM_ SG_ 282 NOP_RearWheelAngleRequestSt "This signal indicates the request status of NOP";
CM_ SG_ 282 NOP_RearWheelReturnReq "This signal indicates the return to 0 request status of NOP";
CM_ SG_ 282 HAD_ObjectDetection "This signal is an ahead target object detected by ACC, to inform the driver.";
CM_ SG_ 282 HAD_TakeOverReq "This signal indicates the request for driver take over if the limits of the ACC /SACC control reaches, ";
CM_ SG_ 282 HAD_CruiseSpeedSetting_ACC "The signal indicates the target speed desired by the driver in ACC cruise mode.";
CM_ SG_ 282 HAD_SysTextinfo "The systerm text information for driver which is displayed in dashboard.";
CM_ SG_ 282 HAD_LDWModeInd "This signal is used to indicates the configure result of LDW function.";
CM_ SG_ 282 HAD_AutoLightModeReq "This signal indicates HAD/HAD request BCM to active the automatic light mode.";
CM_ SG_ 282 HAD_HazardWarningLampRequest "Hazard Warning Lamp request from LCA";
CM_ SG_ 282 HAD_WorkingSt_LDW "This signal indicates the LDW working status.";
CM_ SG_ 282 HAD_WarningCmd_LDW "This signal is warning command for the warning side of lane.";
CM_ SG_ 282 HAD_LDWLaneDetectSt "This signal indicate system lane mark detection status";
CM_ SG_ 282 HAD_SensitivityInd_LDW "This signal indicates current sensitivity of LDW.";
CM_ SG_ 282 HAD_ErrorSt_LDW "This signal indicates the LDW error status.";
CM_ SG_ 282 HAD_WorkingSt_FCW "This signal indicates the FCW system working status.";
CM_ SG_ 282 HAD_DriveAwayReq_L3 "This signal indicates HAD controller request vehicle drive off, ";
CM_ SG_ 282 HAD_StopReq_L3 "This signal indicates HAD controller request vehicle decelerate to standtill,";
CM_ SG_ 282 HAD_AccelerationPedalOverride "This signal indicates the torque demanded by the driver is higher than the torque demanded by NOP.";
CM_ SG_ 282 HAD_SensitivityInd_FCW "This signal indicates current sensitivity of FCW.";
CM_ SG_ 282 HAD_FCWModeInd "This signal is used to indicates the configure result of FCW function.";
CM_ SG_ 282 HAD_WiperAutoLeverReq "This signal indicates that HAD/HAD request BCM1 to turn the wiper to auto lever mode.";
CM_ SG_ 282 HAD_VASFunctionInd "This signal indicates setting result of the configuration of VAS(Vehicle Ahead Start) function.";
CM_ SG_ 282 HAD_SACCNotSatisfiedCondition "This signal indicates the conditions that cant active SACC/ACC function";
CM_ SG_ 282 HAD_LDW_SpeechControlFeedback "This signal indicates the speech control feedback of LDW function setting";
CM_ SG_ 282 HAD_IFCSystemError "This signal indicates the IFC error status.";
CM_ SG_ 282 HAD_IFCCalibrationStatus "This signal indicates the IFC calibration status.";
CM_ SG_ 282 HAD_WarningCmd_VAS "This signal is warning command for the VAS(Vehicle Ahead Start) function.";
CM_ SG_ 282 HAD_LeftTurningLampRequest "Left Turning Lamp request";
CM_ SG_ 282 HAD_RightTurningLampRequest "Right Turning Lamp request";
CM_ SG_ 282 HAD_ValetModeStatus "Indicates the valet mode status";
CM_ SG_ 282 HAD_BrakeModeReq_L3 "This signal indicate HAD request to brake cosily or urgently.
This signal is only used for L3 function";
CM_ SG_ 282 HAD_DrivedownModeReq_L3 "HAD request to quit autodriving funciton.
This signal is only used for L3 function.";
CM_ SG_ 282 HAD_SecureRequest_L3 "HAD request to stop the car safely.
This signal is only used for L3 function";
CM_ SG_ 282 HAD_ErrorSt_AutoDriving_L3 "This signal indicates the L3 autodriving function error status.
This signal is only used for L3 function";
CM_ SG_ 282 HAD_WorkingSt_NOP "This signal indicates the NOP working status.";
CM_ SG_ 282 HAD_ErrorSt_NOP "VDC system capbility for NOP";
CM_ SG_ 282 HAD_ErrorSt_HAD "This signal indicates HAD is error or not.If the value of this signal is °∞Error°Æ,EPS shoud ignore this message and respond the message from VDC.";
CM_ SG_ 282 HAD_AutoDrivingModeReq_NOP "This signal is the Source of Angal request to EPS of NOP function";
CM_ SG_ 282 HAD_AutoDrivingModeReq_NGP "This signal is the Source of Angal request to EPS of NGP function";
CM_ SG_ 282 HAD_SteeringWheelBlendingGain "Blending Gain Factor";
CM_ SG_ 282 HAD_SteeringWheelAngleRequest "Steering Wheel Angle Request";
CM_ SG_ 282 HAD_SteeringWheelAngleSignReques "Steering Wheel Angle Sign Request";
CM_ SG_ 282 HAD_SteeringWheelAngleControlReq "Steering Wheel Angle Control Request";
CM_ SG_ 282 HAD_WorkingSt_NGP "This signal indicates the NGP working status.";
CM_ SG_ 282 HAD_ErrorSt_NGP "HAD system capbility for NGP";
CM_ SG_ 282 LiveCounter_HAD_3 "The Livecounter is used to check the signal consistency of the messages . If the signals are consecutive, the LiveCounter should also be sequential in the way 0, 1, 2 ...X(depends on E2E usage), 0, 1 °≠";
CM_ SG_ 512 CrashInfo "This signal indicates the crash is happened or not. ECUs received the crash info for crash mode.";
CM_ SG_ 512 SysSt_ACU "The signal is sent to IC to display the ACU system information. ";
CM_ SG_ 586 DoorSt_FL "This signal indicates the state of driver door.";
CM_ SG_ 580 SeatBeltSt_DSCU "The signal is sent to indicate the FL Seat Belt is buckled or Unbuckled.";
CM_ SG_ 288 EGSM_ParkButton "This signal indicate the park button in the knob is pressed or not.";
CM_ SG_ 308 Checksum_PDCM_YRS "The checksum is used to check whether the data from the CPU buffer are shifted without transmission errors to the CAN communication controller buffer and vice versa.";
CM_ SG_ 308 YawRate "This signal indicates the yaw rate data (offset value; sign depends on mounting position)
anticlockwise=positive, clockwise=negative";
CM_ SG_ 308 YRSSt "This signal indicates the status of yaw rate sensor";
CM_ SG_ 308 Acceleration_X "The signal is LongitudinalAcceleration(compensated value).Positive value represents  forward,  negative value represents backward. ";
CM_ SG_ 308 Acceleration_Y "The signal is Lateral Acceleration(compensated value).Positive value represents right side of vehicle, negative value represents  left side of vehicle. ";
CM_ SG_ 308 ErrorSt_YRS "This signal indicates if the YRS is error or not.";
CM_ SG_ 308 LiveCounter_PDCM_YRS "The Livecounter is used to check the signal consistency of the messages . If the signals are consecutive, the LiveCounter should also be sequential in the way 0, 1, 2 ...X(depends on E2E usage), 0, 1 °≠";
CM_ SG_ 588 DoorSt_FR "This signal indicates the state of passenger door.";
CM_ SG_ 292 Checksum_YAW_1 "The checksum is used to check whether the data from the CPU buffer are shifted without transmission errors to the CAN communication controller buffer and vice versa.ChecksumFactor=0.";
CM_ SG_ 292 Acceleration_X_ACU "The signal is LongitudinalAcceleration(Raw value,with filtering,without compensated).Positive value represents  forward,  negative value represents backward. ";
CM_ SG_ 292 Acceleration_Y_ACU "The signal is Lateral Acceleration(Raw value,with filtering,without compensated).Positive value represents left side of vehicle, negative value represents  right side of vehicle. ";
CM_ SG_ 292 YawRate_ACU "This signal indicates the yaw rate raw data (RAW data,with filtering,without compensated; sign depends on mounting position)
anticlockwise=positive, clockwise=negative";
CM_ SG_ 292 LatSensorSt "The signal indicates Indicates Lateral Sensor State.";
CM_ SG_ 292 LgtSensorSt "The signal indicates indicates Longitudinal Sensor State";
CM_ SG_ 292 YRSCalibrateSt_ACU "This signal indicates YawRate Sensor Calibration State";
CM_ SG_ 292 YRSSt_ACU "The signal iIndicates YawRate Sensor State";
CM_ SG_ 292 LiveCounter_YAW_1 "The Livecounter is used to check the signal consistency of the messages . If the signals are consecutive, the LiveCounter should also be sequential in the way 0, 1, 2 °≠15, 0, 1 °≠";
CM_ SG_ 640 EPBFunctionSet "This signal is used to set EPB function";
BA_DEF_ BO_  "VFrameFormat" ENUM  "StandardCAN","ExtendedCAN","reserved","reserved","reserved","reserved","reserved","reserved","reserved","reserved","reserved","reserved","reserved","reserved","StandardCAN_FD","ExtendedCAN_FD";
BA_DEF_ BO_  "GenMsgILSupport" ENUM  "No","Yes";
BA_DEF_ BO_  "CanTpSTmin" INT 0 0;
BA_DEF_ BO_  "CanTpFcFrameId" HEX 0 2147483647;
BA_DEF_ BO_  "GenMsgSendType" ENUM  "Cyclic","not_used","not_used","not_used","not_used","Cyclic","not_used","IfActive","NoMsgSendType","Spontaneous","CyclicAndSpontaneous","NoMsgSendType";
BA_DEF_ BO_  "GenMsgCycleTime" INT 0 0;
BA_DEF_ SG_  "GenSigSendType" ENUM  "Cyclic","OnWrite","OnWriteWithRepetition","OnChange","OnChangeWithRepetition","IfActive","IfActiveWithRepetition","NoSigSendType";
BA_DEF_ SG_  "GenSigStartValue" INT 0 0;
BA_DEF_ SG_  "GenSigInvalidValue" INT 0 0;
BA_DEF_ SG_  "GenSigStartRemark" STRING ;
BA_DEF_ SG_  "GenSigInvalidRemark" STRING ;
BA_DEF_ SG_  "SystemSignalLongSymbol" STRING ;
BA_DEF_REL_ BU_SG_REL_  "GenSigTimeoutTime" INT 0 5000;
BA_DEF_DEF_  "VFrameFormat" "ExtendedCAN_FD";
BA_DEF_DEF_  "GenMsgILSupport" "Yes";
BA_DEF_DEF_  "CanTpSTmin" 1;
BA_DEF_DEF_  "CanTpFcFrameId" 2147483647;
BA_DEF_DEF_  "GenMsgSendType" "Cyclic";
BA_DEF_DEF_  "GenMsgCycleTime" 0;
BA_DEF_DEF_  "GenSigSendType" "NoSigSendType";
BA_DEF_DEF_  "GenSigStartValue" 0;
BA_DEF_DEF_  "GenSigInvalidValue" 0;
BA_DEF_DEF_  "GenSigStartRemark" "";
BA_DEF_DEF_  "GenSigInvalidRemark" "";
BA_DEF_DEF_REL_ "GenSigTimeoutTime" 0;
BA_DEF_DEF_  "SystemSignalLongSymbol" "";
BA_ "GenMsgCycleTime" BO_ 169 10;
BA_ "VFrameFormat" BO_ 169 14;
BA_ "GenMsgCycleTime" BO_ 1382 50;
BA_ "VFrameFormat" BO_ 1382 14;
BA_ "GenMsgCycleTime" BO_ 190 10;
BA_ "VFrameFormat" BO_ 190 14;
BA_ "GenMsgCycleTime" BO_ 188 10;
BA_ "VFrameFormat" BO_ 188 14;
BA_ "GenMsgCycleTime" BO_ 189 10;
BA_ "VFrameFormat" BO_ 189 14;
BA_ "GenMsgCycleTime" BO_ 1383 50;
BA_ "VFrameFormat" BO_ 1383 14;
BA_ "GenMsgCycleTime" BO_ 785 150;
BA_ "VFrameFormat" BO_ 785 14;
BA_ "GenMsgCycleTime" BO_ 560 100;
BA_ "VFrameFormat" BO_ 560 14;
BA_ "GenMsgCycleTime" BO_ 562 100;
BA_ "VFrameFormat" BO_ 562 14;
BA_ "GenMsgCycleTime" BO_ 567 100;
BA_ "VFrameFormat" BO_ 567 14;
BA_ "GenMsgCycleTime" BO_ 497 100;
BA_ "VFrameFormat" BO_ 497 14;
BA_ "GenMsgCycleTime" BO_ 532 100;
BA_ "VFrameFormat" BO_ 532 14;
BA_ "GenMsgCycleTime" BO_ 784 150;
BA_ "VFrameFormat" BO_ 784 14;
BA_ "GenMsgCycleTime" BO_ 890 50;
BA_ "VFrameFormat" BO_ 890 14;
BA_ "GenMsgCycleTime" BO_ 688 100;
BA_ "VFrameFormat" BO_ 688 14;
BA_ "GenMsgCycleTime" BO_ 256 20;
BA_ "VFrameFormat" BO_ 256 14;
BA_ "GenMsgCycleTime" BO_ 151 10;
BA_ "VFrameFormat" BO_ 151 14;
BA_ "GenMsgCycleTime" BO_ 290 20;
BA_ "VFrameFormat" BO_ 290 14;
BA_ "GenMsgCycleTime" BO_ 146 10;
BA_ "VFrameFormat" BO_ 146 14;
BA_ "GenMsgCycleTime" BO_ 264 10;
BA_ "VFrameFormat" BO_ 264 14;
BA_ "GenMsgCycleTime" BO_ 147 10;
BA_ "VFrameFormat" BO_ 147 14;
BA_ "GenMsgCycleTime" BO_ 1376 30000;
BA_ "VFrameFormat" BO_ 1376 14;
BA_ "GenMsgCycleTime" BO_ 280 20;
BA_ "VFrameFormat" BO_ 280 14;
BA_ "GenMsgCycleTime" BO_ 282 20;
BA_ "VFrameFormat" BO_ 282 14;
BA_ "GenMsgCycleTime" BO_ 512 100;
BA_ "VFrameFormat" BO_ 512 14;
BA_ "GenMsgCycleTime" BO_ 586 100;
BA_ "VFrameFormat" BO_ 586 14;
BA_ "GenMsgCycleTime" BO_ 580 100;
BA_ "VFrameFormat" BO_ 580 14;
BA_ "GenMsgCycleTime" BO_ 288 20;
BA_ "VFrameFormat" BO_ 288 14;
BA_ "GenMsgCycleTime" BO_ 308 20;
BA_ "VFrameFormat" BO_ 308 14;
BA_ "GenMsgCycleTime" BO_ 588 100;
BA_ "VFrameFormat" BO_ 588 14;
BA_ "GenMsgCycleTime" BO_ 292 10;
BA_ "VFrameFormat" BO_ 292 14;
BA_ "GenMsgCycleTime" BO_ 640 100;
BA_ "VFrameFormat" BO_ 640 14;
BA_ "GenSigStartRemark" SG_ 169 Checksum_RBU_1 "V";
BA_ "GenSigStartValue" SG_ 169 RBU_WheelSpeed_FL 32766;
BA_ "GenSigInvalidValue" SG_ 169 RBU_WheelSpeed_FL 32767;
BA_ "GenSigStartRemark" SG_ 169 RBU_WheelSpeed_FL "O";
BA_ "GenSigInvalidRemark" SG_ 169 RBU_WheelSpeed_FL "O";
BA_ "GenSigStartValue" SG_ 169 RBU_WheelSpeed_FR 32766;
BA_ "GenSigInvalidValue" SG_ 169 RBU_WheelSpeed_FR 32767;
BA_ "GenSigStartRemark" SG_ 169 RBU_WheelSpeed_FR "O";
BA_ "GenSigInvalidRemark" SG_ 169 RBU_WheelSpeed_FR "O";
BA_ "GenSigStartValue" SG_ 169 RBU_WheelSpeed_RL 32766;
BA_ "GenSigInvalidValue" SG_ 169 RBU_WheelSpeed_RL 32767;
BA_ "GenSigStartRemark" SG_ 169 RBU_WheelSpeed_RL "O";
BA_ "GenSigInvalidRemark" SG_ 169 RBU_WheelSpeed_RL "O";
BA_ "GenSigStartValue" SG_ 169 RBU_WheelSpeed_RR 32766;
BA_ "GenSigInvalidValue" SG_ 169 RBU_WheelSpeed_RR 32767;
BA_ "GenSigStartRemark" SG_ 169 RBU_WheelSpeed_RR "O";
BA_ "GenSigInvalidRemark" SG_ 169 RBU_WheelSpeed_RR "O";
BA_ "GenSigInvalidValue" SG_ 169 RBU_BrakePedalStatus 3;
BA_ "GenSigInvalidValue" SG_ 169 RBU_VMC_Error_L3 7;
BA_ "GenSigInvalidValue" SG_ 169 RBU_DrivingDirection 3;
BA_ "GenSigStartValue" SG_ 169 RBU_VehicleSpeed 32766;
BA_ "GenSigInvalidValue" SG_ 169 RBU_VehicleSpeed 32767;
BA_ "GenSigStartRemark" SG_ 169 RBU_VehicleSpeed "O";
BA_ "GenSigInvalidRemark" SG_ 169 RBU_VehicleSpeed "O";
BA_ "GenSigInvalidValue" SG_ 169 RBUIBC_DriveMain2BackupState 15;
BA_ "GenSigInvalidValue" SG_ 169 RBUIBC_StopMain2BackupState 15;
BA_ "GenSigInvalidValue" SG_ 169 RBUIPB_RBUSelfTestInfo 15;
BA_ "GenSigStartRemark" SG_ 190 Checksum_RVA_1 "V";
BA_ "GenSigStartValue" SG_ 190 SteerRearControlAngleReq_RVA 4094;
BA_ "GenSigInvalidValue" SG_ 190 SteerRearControlAngleReq_RVA 4095;
BA_ "GenSigStartRemark" SG_ 188 Checksum_RWS_1 "V";
BA_ "GenSigStartValue" SG_ 785 WiperBrushAngle 254;
BA_ "GenSigInvalidValue" SG_ 785 WiperBrushAngle 255;
BA_ "GenSigStartRemark" SG_ 785 WiperBrushAngle "O";
BA_ "GenSigInvalidRemark" SG_ 785 WiperBrushAngle "O";
BA_ "GenSigStartValue" SG_ 785 WiperBrushSpeed 62;
BA_ "GenSigInvalidValue" SG_ 785 WiperBrushSpeed 63;
BA_ "GenSigStartRemark" SG_ 785 WiperBrushSpeed "O";
BA_ "GenSigInvalidRemark" SG_ 785 WiperBrushSpeed "O";
BA_ "GenSigSendType" SG_ 560 TurningLightCmd_Left 1;
BA_ "GenSigSendType" SG_ 560 TurningLightCmd_Right 1;
BA_ "GenSigSendType" SG_ 560 FlowTurningLightCmd_Left 1;
BA_ "GenSigSendType" SG_ 560 FlowTurningLightCmd_Right 1;
BA_ "GenSigInvalidValue" SG_ 562 PowerMode 15;
BA_ "GenSigStartValue" SG_ 567 CeremonySyncCounter 4094;
BA_ "GenSigInvalidValue" SG_ 567 CeremonySyncCounter 4095;
BA_ "GenSigStartRemark" SG_ 497 Checksum_BCM_FS_Lamp "V";
BA_ "GenSigStartValue" SG_ 532 DMS_ESCModeChangeCmd 1;
BA_ "GenSigSendType" SG_ 532 DMS_ESCModeChangeCmd 1;
BA_ "GenSigStartValue" SG_ 532 DMS_EPSModeChangeCmd 3;
BA_ "GenSigSendType" SG_ 532 DMS_EPSModeChangeCmd 1;
BA_ "GenSigStartValue" SG_ 784 VehicleSpeed_WMM 254;
BA_ "GenSigInvalidValue" SG_ 784 VehicleSpeed_WMM 255;
BA_ "GenSigStartRemark" SG_ 784 VehicleSpeed_WMM "O";
BA_ "GenSigInvalidRemark" SG_ 784 VehicleSpeed_WMM "O";
BA_ "GenSigStartValue" SG_ 784 AmbientTemp_WMM 254;
BA_ "GenSigInvalidValue" SG_ 784 AmbientTemp_WMM 255;
BA_ "GenSigStartRemark" SG_ 784 AmbientTemp_WMM "O";
BA_ "GenSigInvalidRemark" SG_ 784 AmbientTemp_WMM "O";
BA_ "GenSigStartRemark" SG_ 784 RainLightSensorStatus "L";
BA_ "GenSigStartValue" SG_ 688 VDC_IgnitionOffTime 4094;
BA_ "GenSigInvalidValue" SG_ 688 VDC_IgnitionOffTime 4095;
BA_ "GenSigStartRemark" SG_ 688 VDC_IgnitionOffTime "O";
BA_ "GenSigInvalidRemark" SG_ 688 VDC_IgnitionOffTime "O";
BA_ "GenSigInvalidValue" SG_ 688 VDC_VehicleMode 15;
BA_ "GenSigInvalidValue" SG_ 688 VDC_PowerMode 15;
BA_ "GenSigStartRemark" SG_ 256 Checksum_ADV_2 "V";
BA_ "GenSigStartRemark" SG_ 256 ADV_WorkingSt_APA "L";
BA_ "GenSigStartRemark" SG_ 256 ADV_WorkingSt_RPA "L";
BA_ "GenSigStartRemark" SG_ 256 ADV_WorkingSt_AVP "L";
BA_ "GenSigInvalidValue" SG_ 256 ADV_SteeringWheelAngleRequest 32767;
BA_ "GenSigInvalidRemark" SG_ 256 ADV_SteeringWheelAngleRequest "O";
BA_ "SystemSignalLongSymbol" SG_ 256 ADV_SteeringWheelAngleSignReques "ADV_SteeringWheelAngleSignRequest";
BA_ "SystemSignalLongSymbol" SG_ 256 ADV_SteeringWheelAngleControlReq "ADV_SteeringWheelAngleControlRequest";
BA_ "GenSigStartValue" SG_ 256 ADV_RearWheelAngleRequest 4094;
BA_ "GenSigInvalidValue" SG_ 256 ADV_RearWheelAngleRequest 4095;
BA_ "GenSigInvalidValue" SG_ 256 APA_FailureBrakeMode 7;
BA_ "GenSigStartRemark" SG_ 151 Checksum_HCU_2_10 "V";
BA_ "GenSigStartValue" SG_ 151 HCU_MCU1TMSpeed 65534;
BA_ "GenSigInvalidValue" SG_ 151 HCU_MCU1TMSpeed 65535;
BA_ "GenSigStartValue" SG_ 151 HCU_FrontWheelActTorque 16382;
BA_ "GenSigInvalidValue" SG_ 151 HCU_FrontWheelActTorque 16383;
BA_ "GenSigStartValue" SG_ 151 HCU_FrontWheelMaxDriveTorque 8190;
BA_ "GenSigInvalidValue" SG_ 151 HCU_FrontWheelMaxDriveTorque 8191;
BA_ "GenSigStartValue" SG_ 151 HCU_FrontWheelMaxBrakeRegTorque 8190;
BA_ "GenSigInvalidValue" SG_ 151 HCU_FrontWheelMaxBrakeRegTorque 8191;
BA_ "GenSigStartValue" SG_ 151 HCU_FrontWheelBrakeRegTorque 8190;
BA_ "GenSigInvalidValue" SG_ 151 HCU_FrontWheelBrakeRegTorque 8191;
BA_ "GenSigStartValue" SG_ 151 HCU_MCU2TMSpeed 65534;
BA_ "GenSigInvalidValue" SG_ 151 HCU_MCU2TMSpeed 65535;
BA_ "GenSigStartValue" SG_ 151 HCU_RearWheelActTorque 16382;
BA_ "GenSigInvalidValue" SG_ 151 HCU_RearWheelActTorque 16383;
BA_ "GenSigStartValue" SG_ 151 HCU_RearWheelMaxDriveTorque 8190;
BA_ "GenSigInvalidValue" SG_ 151 HCU_RearWheelMaxDriveTorque 8191;
BA_ "GenSigStartValue" SG_ 151 HCU_RearWheelMaxBrakeRegTorque 8190;
BA_ "GenSigInvalidValue" SG_ 151 HCU_RearWheelMaxBrakeRegTorque 8191;
BA_ "GenSigStartValue" SG_ 151 HCU_RearWheelBrakeRegTorque 8190;
BA_ "GenSigInvalidValue" SG_ 151 HCU_RearWheelBrakeRegTorque 8191;
BA_ "GenSigStartRemark" SG_ 290 Checksum_HCU_2_12 "V";
BA_ "GenSigStartValue" SG_ 290 HCU2_LeverInfo 5;
BA_ "GenSigInvalidValue" SG_ 290 HCU2_LeverInfo 7;
BA_ "GenSigStartRemark" SG_ 146 Checksum_HCU_2_2 "V";
BA_ "GenSigInvalidValue" SG_ 146 HCU_EPBLeverRequest 7;
BA_ "GenSigStartValue" SG_ 146 HCU_AccelerationPedalPosition 254;
BA_ "GenSigInvalidValue" SG_ 146 HCU_AccelerationPedalPosition 255;
BA_ "GenSigStartValue" SG_ 146 HCU_CalcAccelerationPedalPositio 254;
BA_ "GenSigInvalidValue" SG_ 146 HCU_CalcAccelerationPedalPositio 255;
BA_ "SystemSignalLongSymbol" SG_ 146 HCU_CalcAccelerationPedalPositio "HCU_CalcAccelerationPedalPosition";
BA_ "GenSigInvalidValue" SG_ 146 LiveCounter_HCU_2_2 15;
BA_ "GenSigStartRemark" SG_ 264 Checksum_HCU_2_4 "V";
BA_ "GenSigStartValue" SG_ 264 HCU_DriverTorq_FrontWheel 65534;
BA_ "GenSigInvalidValue" SG_ 264 HCU_DriverTorq_FrontWheel 65535;
BA_ "GenSigInvalidValue" SG_ 264 HCU_CruiseControlSt 3;
BA_ "GenSigStartValue" SG_ 264 HCU_DriverTorq_RearWheel 65534;
BA_ "GenSigInvalidValue" SG_ 264 HCU_DriverTorq_RearWheel 65535;
BA_ "GenSigStartValue" SG_ 264 HCU_GradientAccelerationPedal 254;
BA_ "GenSigInvalidValue" SG_ 264 HCU_GradientAccelerationPedal 255;
BA_ "GenSigStartRemark" SG_ 264 HCU_GradientAccelerationPedal "O";
BA_ "GenSigInvalidRemark" SG_ 264 HCU_GradientAccelerationPedal "O";
BA_ "SystemSignalLongSymbol" SG_ 147 HCU_SlipContrlIntervention_Front "HCU_SlipContrlIntervention_FrontAxle";
BA_ "SystemSignalLongSymbol" SG_ 147 HCU_SlipContrlIntervention_RearA "HCU_SlipContrlIntervention_RearAxle";
BA_ "GenSigStartRemark" SG_ 280 Checksum_VDC_1 "V";
BA_ "GenSigStartRemark" SG_ 280 VDC_WorkingSt_LKA "L";
BA_ "GenSigStartValue" SG_ 280 VDC_WorkingSt_AEB_L12 1;
BA_ "GenSigStartValue" SG_ 280 VDC_SpeedChangeRequest_L12 2046;
BA_ "GenSigInvalidValue" SG_ 280 VDC_SpeedChangeRequest_L12 2047;
BA_ "GenSigStartRemark" SG_ 280 VDC_CruiseModeFunctionInd "L";
BA_ "GenSigStartValue" SG_ 280 VDC_DecelerationReq_AEB 1022;
BA_ "GenSigInvalidValue" SG_ 280 VDC_DecelerationReq_AEB 1023;
BA_ "GenSigStartRemark" SG_ 280 VDC_DecelerationReq_AEB "O";
BA_ "GenSigInvalidRemark" SG_ 280 VDC_DecelerationReq_AEB "O";
BA_ "GenSigStartRemark" SG_ 280 VDC_WorkingSt_LCA "L";
BA_ "GenSigStartValue" SG_ 280 VDC_SteeringTorqueRequest 1022;
BA_ "GenSigInvalidValue" SG_ 280 VDC_SteeringTorqueRequest 1023;
BA_ "GenSigStartRemark" SG_ 280 VDC_WorkingSt_SACC "L";
BA_ "GenSigStartRemark" SG_ 280 VDC_WorkingSt_DCLC "L";
BA_ "GenSigStartRemark" SG_ 280 VDC_WorkingSt_EMA "L";
BA_ "GenSigInvalidValue" SG_ 280 VDC_SteeringWheelAngleRequest 32767;
BA_ "GenSigInvalidRemark" SG_ 280 VDC_SteeringWheelAngleRequest "O";
BA_ "SystemSignalLongSymbol" SG_ 280 VDC_SteeringWheelAngleSignReques "VDC_SteeringWheelAngleSignRequest";
BA_ "GenSigInvalidValue" SG_ 280 VDC_SteeringWheelBlendingGain 255;
BA_ "GenSigStartValue" SG_ 280 VDC_SteeringMaxTorqueRequest 1022;
BA_ "GenSigInvalidValue" SG_ 280 VDC_SteeringMaxTorqueRequest 1023;
BA_ "GenSigStartRemark" SG_ 280 VDC_SteeringMaxTorqueRequest "O";
BA_ "GenSigInvalidRemark" SG_ 280 VDC_SteeringMaxTorqueRequest "O";
BA_ "GenSigStartValue" SG_ 280 SACC_RearWheelAngleRequest 4094;
BA_ "GenSigInvalidValue" SG_ 280 SACC_RearWheelAngleRequest 4095;
BA_ "GenSigStartValue" SG_ 280 LKA_RearWheelAngleRequest 4094;
BA_ "GenSigInvalidValue" SG_ 280 LKA_RearWheelAngleRequest 4095;
BA_ "GenSigStartValue" SG_ 280 VDC_WorkingSt_FCW 1;
BA_ "GenSigStartRemark" SG_ 282 Checksum_HAD_3 "V";
BA_ "GenSigStartValue" SG_ 282 HAD_SpeedChangeRequest_L3 2046;
BA_ "GenSigInvalidValue" SG_ 282 HAD_SpeedChangeRequest_L3 2047;
BA_ "GenSigStartValue" SG_ 282 HAD_TimeGapSetting 3;
BA_ "GenSigSendType" SG_ 282 HAD_TimeGapSetting 1;
BA_ "GenSigStartValue" SG_ 282 NOP_RearWheelAngleRequest 4094;
BA_ "GenSigInvalidValue" SG_ 282 NOP_RearWheelAngleRequest 4095;
BA_ "GenSigSendType" SG_ 282 HAD_TakeOverReq 1;
BA_ "GenSigStartValue" SG_ 282 HAD_CruiseSpeedSetting_ACC 254;
BA_ "GenSigInvalidValue" SG_ 282 HAD_CruiseSpeedSetting_ACC 255;
BA_ "GenSigStartRemark" SG_ 282 HAD_CruiseSpeedSetting_ACC "O";
BA_ "GenSigInvalidRemark" SG_ 282 HAD_CruiseSpeedSetting_ACC "O";
BA_ "GenSigStartRemark" SG_ 282 HAD_LDWModeInd "L";
BA_ "GenSigSendType" SG_ 282 HAD_AutoLightModeReq 1;
BA_ "GenSigSendType" SG_ 282 HAD_HazardWarningLampRequest 1;
BA_ "GenSigStartValue" SG_ 282 HAD_WorkingSt_LDW 1;
BA_ "GenSigSendType" SG_ 282 HAD_WarningCmd_LDW 1;
BA_ "GenSigStartRemark" SG_ 282 HAD_SensitivityInd_LDW "L";
BA_ "GenSigStartValue" SG_ 282 HAD_WorkingSt_FCW 1;
BA_ "GenSigStartRemark" SG_ 282 HAD_SensitivityInd_FCW "L";
BA_ "GenSigStartValue" SG_ 282 HAD_FCWModeInd 1;
BA_ "GenSigSendType" SG_ 282 HAD_LDW_SpeechControlFeedback 1;
BA_ "GenSigStartRemark" SG_ 282 HAD_ValetModeStatus "L";
BA_ "GenSigStartRemark" SG_ 282 HAD_WorkingSt_NOP "L";
BA_ "GenSigInvalidValue" SG_ 282 HAD_SteeringWheelBlendingGain 255;
BA_ "GenSigInvalidValue" SG_ 282 HAD_SteeringWheelAngleRequest 32767;
BA_ "GenSigInvalidRemark" SG_ 282 HAD_SteeringWheelAngleRequest "O";
BA_ "SystemSignalLongSymbol" SG_ 282 HAD_SteeringWheelAngleSignReques "HAD_SteeringWheelAngleSignRequest";
BA_ "SystemSignalLongSymbol" SG_ 282 HAD_SteeringWheelAngleControlReq "HAD_SteeringWheelAngleControlRequest";
BA_ "GenSigStartRemark" SG_ 282 HAD_WorkingSt_NGP "L";
BA_ "GenSigSendType" SG_ 512 CrashInfo 1;
BA_ "GenSigStartRemark" SG_ 308 Checksum_PDCM_YRS "V";
BA_ "GenSigStartValue" SG_ 308 YawRate 4094;
BA_ "GenSigInvalidValue" SG_ 308 YawRate 4095;
BA_ "GenSigStartValue" SG_ 308 Acceleration_X 2046;
BA_ "GenSigInvalidValue" SG_ 308 Acceleration_X 2047;
BA_ "GenSigStartValue" SG_ 308 Acceleration_Y 2046;
BA_ "GenSigInvalidValue" SG_ 308 Acceleration_Y 2047;
BA_ "GenSigStartRemark" SG_ 292 Checksum_YAW_1 "V";
BA_ "GenSigStartValue" SG_ 292 Acceleration_X_ACU 2000;
BA_ "GenSigInvalidValue" SG_ 292 Acceleration_X_ACU 4095;
BA_ "GenSigStartValue" SG_ 292 Acceleration_Y_ACU 2000;
BA_ "GenSigInvalidValue" SG_ 292 Acceleration_Y_ACU 4095;
BA_ "GenSigStartValue" SG_ 292 YawRate_ACU 18000;
BA_ "GenSigInvalidValue" SG_ 292 YawRate_ACU 65535;
BA_REL_ "GenSigTimeoutTime" BU_SG_REL_ HAD3971 SG_ 169 Checksum_RBU_1 100;
BA_REL_ "GenSigTimeoutTime" BU_SG_REL_ HAD3971 SG_ 169 RBU_WheelSpeed_FL 100;
BA_REL_ "GenSigTimeoutTime" BU_SG_REL_ HAD3971 SG_ 169 RBU_WheelSpeed_FR 100;
BA_REL_ "GenSigTimeoutTime" BU_SG_REL_ HAD3971 SG_ 169 RBU_WheelSpeed_RL 100;
BA_REL_ "GenSigTimeoutTime" BU_SG_REL_ HAD3971 SG_ 169 RBU_WheelSpeed_RR 100;
BA_REL_ "GenSigTimeoutTime" BU_SG_REL_ HAD3971 SG_ 169 RBU_ErrorSt_SBS 100;
BA_REL_ "GenSigTimeoutTime" BU_SG_REL_ HAD3971 SG_ 169 RBU_Intervention_SBS 100;
BA_REL_ "GenSigTimeoutTime" BU_SG_REL_ HAD3971 SG_ 169 RBU_EPBAvailableSt_L3 100;
BA_REL_ "GenSigTimeoutTime" BU_SG_REL_ HAD3971 SG_ 169 RBU_UsedChannel_L3 100;
BA_REL_ "GenSigTimeoutTime" BU_SG_REL_ HAD3971 SG_ 169 RBU_ControllerReleaseSt_L3 100;
BA_REL_ "GenSigTimeoutTime" BU_SG_REL_ HAD3971 SG_ 169 RBU_SuspendStatusByDriver_L3 100;
BA_REL_ "GenSigTimeoutTime" BU_SG_REL_ HAD3971 SG_ 169 RBU_BrakePedalStatus_Q 100;
BA_REL_ "GenSigTimeoutTime" BU_SG_REL_ HAD3971 SG_ 169 RBU_BrakePedalStatus 100;
BA_REL_ "GenSigTimeoutTime" BU_SG_REL_ HAD3971 SG_ 169 RBU_VLCSt 100;
BA_REL_ "GenSigTimeoutTime" BU_SG_REL_ HAD3971 SG_ 169 RBU_VMC_Error_L3 100;
BA_REL_ "GenSigTimeoutTime" BU_SG_REL_ HAD3971 SG_ 169 RBU_DrivingDirection 100;
BA_REL_ "GenSigTimeoutTime" BU_SG_REL_ HAD3971 SG_ 169 RBU_VehicleSpeed 100;
BA_REL_ "GenSigTimeoutTime" BU_SG_REL_ HAD3971 SG_ 169 RBU_TargetGearReq_VMC_1 100;
BA_REL_ "GenSigTimeoutTime" BU_SG_REL_ HAD3971 SG_ 169 RBU_TargetGearReqEnable_VMC_1 100;
BA_REL_ "GenSigTimeoutTime" BU_SG_REL_ HAD3971 SG_ 169 RBU_VehicleStandstillSt 100;
BA_REL_ "GenSigTimeoutTime" BU_SG_REL_ HAD3971 SG_ 169 RBU_BrakeLightCtrlCmd 100;
BA_REL_ "GenSigTimeoutTime" BU_SG_REL_ HAD3971 SG_ 169 LiveCounter_RBU_1 100;
BA_REL_ "GenSigTimeoutTime" BU_SG_REL_ VDC397 SG_ 1382 SECOC_FVReqCode_RBU 500;
BA_REL_ "GenSigTimeoutTime" BU_SG_REL_ VDC397 SG_ 190 Checksum_RVA_1 100;
BA_REL_ "GenSigTimeoutTime" BU_SG_REL_ HAD3971 SG_ 190 Checksum_RVA_1 100;
BA_REL_ "GenSigTimeoutTime" BU_SG_REL_ VDC397 SG_ 190 SteerRearControlAngleReq_RVA 100;
BA_REL_ "GenSigTimeoutTime" BU_SG_REL_ HAD3971 SG_ 190 SteerRearControlAngleReq_RVA 100;
BA_REL_ "GenSigTimeoutTime" BU_SG_REL_ VDC397 SG_ 190 SteerRearControlSt_RVA 100;
BA_REL_ "GenSigTimeoutTime" BU_SG_REL_ HAD3971 SG_ 190 SteerRearControlSt_RVA 100;
BA_REL_ "GenSigTimeoutTime" BU_SG_REL_ VDC397 SG_ 190 WorkingSt_RVA 100;
BA_REL_ "GenSigTimeoutTime" BU_SG_REL_ HAD3971 SG_ 190 WorkingSt_RVA 100;
BA_REL_ "GenSigTimeoutTime" BU_SG_REL_ VDC397 SG_ 190 BehaviorMode_RVA 100;
BA_REL_ "GenSigTimeoutTime" BU_SG_REL_ HAD3971 SG_ 190 BehaviorMode_RVA 100;
BA_REL_ "GenSigTimeoutTime" BU_SG_REL_ VDC397 SG_ 190 ErrorSt_RVA 100;
BA_REL_ "GenSigTimeoutTime" BU_SG_REL_ HAD3971 SG_ 190 ErrorSt_RVA 100;
BA_REL_ "GenSigTimeoutTime" BU_SG_REL_ VDC397 SG_ 190 IBCControlAvailable_RVA 100;
BA_REL_ "GenSigTimeoutTime" BU_SG_REL_ HAD3971 SG_ 190 IBCControlAvailable_RVA 100;
BA_REL_ "GenSigTimeoutTime" BU_SG_REL_ VDC397 SG_ 190 APAControlSt_RVA 100;
BA_REL_ "GenSigTimeoutTime" BU_SG_REL_ HAD3971 SG_ 190 APAControlSt_RVA 100;
BA_REL_ "GenSigTimeoutTime" BU_SG_REL_ VDC397 SG_ 190 APAAbortFeedback_RVA 100;
BA_REL_ "GenSigTimeoutTime" BU_SG_REL_ HAD3971 SG_ 190 APAAbortFeedback_RVA 100;
BA_REL_ "GenSigTimeoutTime" BU_SG_REL_ VDC397 SG_ 190 SACCControlSt_RVA 100;
BA_REL_ "GenSigTimeoutTime" BU_SG_REL_ HAD3971 SG_ 190 SACCControlSt_RVA 100;
BA_REL_ "GenSigTimeoutTime" BU_SG_REL_ VDC397 SG_ 190 LKAControlSt_RVA 100;
BA_REL_ "GenSigTimeoutTime" BU_SG_REL_ HAD3971 SG_ 190 LKAControlSt_RVA 100;
BA_REL_ "GenSigTimeoutTime" BU_SG_REL_ VDC397 SG_ 190 NOPControlSt_RVA 100;
BA_REL_ "GenSigTimeoutTime" BU_SG_REL_ HAD3971 SG_ 190 NOPControlSt_RVA 100;
BA_REL_ "GenSigTimeoutTime" BU_SG_REL_ VDC397 SG_ 190 Livecounter_RVA_1 100;
BA_REL_ "GenSigTimeoutTime" BU_SG_REL_ HAD3971 SG_ 190 Livecounter_RVA_1 100;
BA_REL_ "GenSigTimeoutTime" BU_SG_REL_ VDC397 SG_ 190 SECOC_FV_RVA_1 100;
BA_REL_ "GenSigTimeoutTime" BU_SG_REL_ VDC397 SG_ 190 SECOC_TMAC_RVA_1 100;
BA_REL_ "GenSigTimeoutTime" BU_SG_REL_ HAD3971 SG_ 188 Checksum_RWS_1 100;
BA_REL_ "GenSigTimeoutTime" BU_SG_REL_ HAD3971 SG_ 188 RearWheelAngle 100;
BA_REL_ "GenSigTimeoutTime" BU_SG_REL_ HAD3971 SG_ 188 RearWheelAngle_QF 100;
BA_REL_ "GenSigTimeoutTime" BU_SG_REL_ HAD3971 SG_ 188 RearWheelAngleSpeed 100;
BA_REL_ "GenSigTimeoutTime" BU_SG_REL_ HAD3971 SG_ 188 WorkingSt_RWS 100;
BA_REL_ "GenSigTimeoutTime" BU_SG_REL_ HAD3971 SG_ 188 ErrorSt_RWS 100;
BA_REL_ "GenSigTimeoutTime" BU_SG_REL_ HAD3971 SG_ 188 LiveCounter_RWS_1 100;
BA_REL_ "GenSigTimeoutTime" BU_SG_REL_ VDC397 SG_ 188 SECOC_FV_RWS_1 100;
BA_REL_ "GenSigTimeoutTime" BU_SG_REL_ VDC397 SG_ 188 SECOC_TMAC_RWS_1 100;
BA_REL_ "GenSigTimeoutTime" BU_SG_REL_ HAD3971 SG_ 189 MaxAngle_RWS 100;
BA_REL_ "GenSigTimeoutTime" BU_SG_REL_ HAD3971 SG_ 189 MaxAngleGrad_RWS 100;
BA_REL_ "GenSigTimeoutTime" BU_SG_REL_ VDC397 SG_ 1383 SECOC_FVReqCode_RWS 500;
BA_REL_ "GenSigTimeoutTime" BU_SG_REL_ VDC821 SG_ 785 WiperBrushAngle 1500;
BA_REL_ "GenSigTimeoutTime" BU_SG_REL_ VDC821 SG_ 785 WiperBrushSpeed 1500;
BA_REL_ "GenSigTimeoutTime" BU_SG_REL_ VDC821 SG_ 785 WiperMotorSt 1500;
BA_REL_ "GenSigTimeoutTime" BU_SG_REL_ VDC821 SG_ 785 WiperParkPosition 1500;
BA_REL_ "GenSigTimeoutTime" BU_SG_REL_ VDC821 SG_ 785 ServicePosition_WMM 1500;
BA_REL_ "GenSigTimeoutTime" BU_SG_REL_ VDC821 SG_ 785 WiperTurnningPosition 1500;
BA_REL_ "GenSigTimeoutTime" BU_SG_REL_ VDC821 SG_ 785 LINError_WMM 1500;
BA_REL_ "GenSigTimeoutTime" BU_SG_REL_ VDC821 SG_ 785 WMMFaultSt 1500;
BA_REL_ "GenSigTimeoutTime" BU_SG_REL_ PDCF SG_ 560 TurningLightCmd_Left 1000;
BA_REL_ "GenSigTimeoutTime" BU_SG_REL_ PDCF SG_ 560 TurningLightCmd_Right 1000;
BA_REL_ "GenSigTimeoutTime" BU_SG_REL_ PDCF SG_ 560 FlowTurningLightCmd_Left 1000;
BA_REL_ "GenSigTimeoutTime" BU_SG_REL_ PDCF SG_ 560 FlowTurningLightCmd_Right 1000;
BA_REL_ "GenSigTimeoutTime" BU_SG_REL_ PDCF SG_ 562 PowerMode 1000;
BA_REL_ "GenSigTimeoutTime" BU_SG_REL_ PDCF SG_ 567 PositionLightCmd_FL 1000;
BA_REL_ "GenSigTimeoutTime" BU_SG_REL_ PDCF SG_ 567 PositionLightCmd_FR 1000;
BA_REL_ "GenSigTimeoutTime" BU_SG_REL_ PDCF SG_ 567 DayRunningLightCmd_Left 1000;
BA_REL_ "GenSigTimeoutTime" BU_SG_REL_ PDCF SG_ 567 DayRunningLightCmd_Right 1000;
BA_REL_ "GenSigTimeoutTime" BU_SG_REL_ PDCF SG_ 567 HighBeamCmd_Left 1000;
BA_REL_ "GenSigTimeoutTime" BU_SG_REL_ PDCF SG_ 567 HighBeamCmd_Right 1000;
BA_REL_ "GenSigTimeoutTime" BU_SG_REL_ PDCF SG_ 567 FrontFogCmd_Left 1000;
BA_REL_ "GenSigTimeoutTime" BU_SG_REL_ PDCF SG_ 567 FrontFogCmd_Right 1000;
BA_REL_ "GenSigTimeoutTime" BU_SG_REL_ PDCF SG_ 567 FlowDayRunningLightCmd_Left 1000;
BA_REL_ "GenSigTimeoutTime" BU_SG_REL_ PDCF SG_ 567 FlowDayRunningLightCmd_Right 1000;
BA_REL_ "GenSigTimeoutTime" BU_SG_REL_ PDCF SG_ 567 ADS_LightCmd 1000;
BA_REL_ "GenSigTimeoutTime" BU_SG_REL_ PDCF SG_ 567 CeremonyScenarioSet 1000;
BA_REL_ "GenSigTimeoutTime" BU_SG_REL_ PDCF SG_ 567 CornerLampCmd_Right 1000;
BA_REL_ "GenSigTimeoutTime" BU_SG_REL_ PDCF SG_ 567 CornerLampCmd_Left 1000;
BA_REL_ "GenSigTimeoutTime" BU_SG_REL_ PDCF SG_ 567 CeremonyModeSet 1000;
BA_REL_ "GenSigTimeoutTime" BU_SG_REL_ PDCF SG_ 567 CeremonySyncCounter 1000;
BA_REL_ "GenSigTimeoutTime" BU_SG_REL_ PDCF SG_ 497 Checksum_BCM_FS_Lamp 1000;
BA_REL_ "GenSigTimeoutTime" BU_SG_REL_ PDCF SG_ 497 LowBeamCmd_Left 1000;
BA_REL_ "GenSigTimeoutTime" BU_SG_REL_ PDCF SG_ 497 LowBeamCmd_Right 1000;
BA_REL_ "GenSigTimeoutTime" BU_SG_REL_ PDCF SG_ 497 LiveCounter_BCM_FS_Lamp 1000;
BA_REL_ "GenSigTimeoutTime" BU_SG_REL_ PDCF SG_ 532 DMS_ESCModeChangeCmd 1000;
BA_REL_ "GenSigTimeoutTime" BU_SG_REL_ PDCF SG_ 532 DMS_EPSModeChangeCmd 1000;
BA_REL_ "GenSigTimeoutTime" BU_SG_REL_ PDCF SG_ 784 WiperSwitch 1500;
BA_REL_ "GenSigTimeoutTime" BU_SG_REL_ PDCF SG_ 784 WashSwitch_FrontWindow 1500;
BA_REL_ "GenSigTimeoutTime" BU_SG_REL_ PDCF SG_ 784 WiperSwitch_SensitiveLevel 1500;
BA_REL_ "GenSigTimeoutTime" BU_SG_REL_ PDCF SG_ 784 VehicleSpeed_WMM 1500;
BA_REL_ "GenSigTimeoutTime" BU_SG_REL_ PDCF SG_ 784 AmbientTemp_WMM 1500;
BA_REL_ "GenSigTimeoutTime" BU_SG_REL_ PDCF SG_ 784 AutoWiperSpeed 1500;
BA_REL_ "GenSigTimeoutTime" BU_SG_REL_ PDCF SG_ 784 Splash_WMM 1500;
BA_REL_ "GenSigTimeoutTime" BU_SG_REL_ PDCF SG_ 784 RainLightSensorStatus 1500;
BA_REL_ "GenSigTimeoutTime" BU_SG_REL_ PDCF SG_ 784 EngineHoodSt 1500;
BA_REL_ "GenSigTimeoutTime" BU_SG_REL_ PDCF SG_ 784 ServicePositionCmd 1500;
BA_REL_ "GenSigTimeoutTime" BU_SG_REL_ PDCF SG_ 784 IgnitionState 1500;
BA_REL_ "GenSigTimeoutTime" BU_SG_REL_ PDCF SG_ 784 CrankingState 1500;
BA_REL_ "GenSigTimeoutTime" BU_SG_REL_ PDCF SG_ 890 SignLamp1_Cmd 500;
BA_REL_ "GenSigTimeoutTime" BU_SG_REL_ PDCF SG_ 890 SignLamp2_Cmd 500;
BA_REL_ "GenSigTimeoutTime" BU_SG_REL_ PDCF SG_ 688 VDC_IgnitionOffTime 1000;
BA_REL_ "GenSigTimeoutTime" BU_SG_REL_ PDCF SG_ 688 VDC_RemoteVehicleMode 1000;
BA_REL_ "GenSigTimeoutTime" BU_SG_REL_ PDCF SG_ 688 VDC_OTAMode 1000;
BA_REL_ "GenSigTimeoutTime" BU_SG_REL_ PDCF SG_ 688 VDC_VehicleMode 1000;
BA_REL_ "GenSigTimeoutTime" BU_SG_REL_ PDCF SG_ 688 VDC_PowerMode 1000;
BA_REL_ "GenSigTimeoutTime" BU_SG_REL_ PDCF SG_ 256 Checksum_ADV_2 200;
BA_REL_ "GenSigTimeoutTime" BU_SG_REL_ PDCF SG_ 256 ADV_ErrorSt_EPS 200;
BA_REL_ "GenSigTimeoutTime" BU_SG_REL_ PDCF SG_ 256 ADV_AutoParkingModeReq 200;
BA_REL_ "GenSigTimeoutTime" BU_SG_REL_ PDCF SG_ 256 ADV_AutoParkingRequestSt 200;
BA_REL_ "GenSigTimeoutTime" BU_SG_REL_ PDCF SG_ 256 APA_DriverInterventionSt 200;
BA_REL_ "GenSigTimeoutTime" BU_SG_REL_ PDCF SG_ 256 ADV_ErrorSt_APA 200;
BA_REL_ "GenSigTimeoutTime" BU_SG_REL_ PDCF SG_ 256 ADV_ErrorSt_RPA 200;
BA_REL_ "GenSigTimeoutTime" BU_SG_REL_ PDCF SG_ 256 ADV_ErrorSt_AVP 200;
BA_REL_ "GenSigTimeoutTime" BU_SG_REL_ PDCF SG_ 256 ADV_ErrorSt_RVA 200;
BA_REL_ "GenSigTimeoutTime" BU_SG_REL_ PDCF SG_ 256 ADV_WorkingSt_APA 200;
BA_REL_ "GenSigTimeoutTime" BU_SG_REL_ PDCF SG_ 256 ADV_WorkingSt_RPA 200;
BA_REL_ "GenSigTimeoutTime" BU_SG_REL_ PDCF SG_ 256 ADV_WorkingSt_AVP 200;
BA_REL_ "GenSigTimeoutTime" BU_SG_REL_ PDCF SG_ 256 APA_SecureRequest 200;
BA_REL_ "GenSigTimeoutTime" BU_SG_REL_ PDCF SG_ 256 APA_AutoParkingReq 200;
BA_REL_ "GenSigTimeoutTime" BU_SG_REL_ PDCF SG_ 256 APA_DirectionCmd 200;
BA_REL_ "GenSigTimeoutTime" BU_SG_REL_ PDCF SG_ 256 ADV_SteeringWheelAngleRequest 200;
BA_REL_ "GenSigTimeoutTime" BU_SG_REL_ PDCF SG_ 256 ADV_SteeringWheelAngleSignReques 200;
BA_REL_ "GenSigTimeoutTime" BU_SG_REL_ PDCF SG_ 256 ADV_SteeringWheelAngleControlReq 200;
BA_REL_ "GenSigTimeoutTime" BU_SG_REL_ PDCF SG_ 256 ADV_RearWheelAngleRequestSt 200;
BA_REL_ "GenSigTimeoutTime" BU_SG_REL_ PDCF SG_ 256 ADV_RearWheelAngleRequest 200;
BA_REL_ "GenSigTimeoutTime" BU_SG_REL_ PDCF SG_ 256 APA_BrakeFunctionMode 200;
BA_REL_ "GenSigTimeoutTime" BU_SG_REL_ PDCF SG_ 256 APA_StopDistance 200;
BA_REL_ "GenSigTimeoutTime" BU_SG_REL_ PDCF SG_ 256 APA_SpeedLimitation 200;
BA_REL_ "GenSigTimeoutTime" BU_SG_REL_ PDCF SG_ 256 APA_FailureBrakeMode 200;
BA_REL_ "GenSigTimeoutTime" BU_SG_REL_ PDCF SG_ 256 APA_EPBLockedRequest 200;
BA_REL_ "GenSigTimeoutTime" BU_SG_REL_ PDCF SG_ 256 APA_EPBRequestEnable 200;
BA_REL_ "GenSigTimeoutTime" BU_SG_REL_ PDCF SG_ 256 LiveCounter_ADV_2 200;
BA_REL_ "GenSigTimeoutTime" BU_SG_REL_ PDCF SG_ 256 SECOC_FV_ADV_2 200;
BA_REL_ "GenSigTimeoutTime" BU_SG_REL_ PDCF SG_ 256 SECOC_TMAC_ADV_2 200;
BA_REL_ "GenSigTimeoutTime" BU_SG_REL_ PDCF SG_ 151 Checksum_HCU_2_10 100;
BA_REL_ "GenSigTimeoutTime" BU_SG_REL_ PDCF SG_ 151 HCU_MCU1TMSpeed 100;
BA_REL_ "GenSigTimeoutTime" BU_SG_REL_ PDCF SG_ 151 HCU_FrontWheelActTorque 100;
BA_REL_ "GenSigTimeoutTime" BU_SG_REL_ PDCF SG_ 151 HCU_FrontWheelActTorqueSt 100;
BA_REL_ "GenSigTimeoutTime" BU_SG_REL_ PDCF SG_ 151 HCU_FrontWheelMaxDriveTorque 100;
BA_REL_ "GenSigTimeoutTime" BU_SG_REL_ PDCF SG_ 151 HCU_FrontWheelMaxDriveTorqueSt 100;
BA_REL_ "GenSigTimeoutTime" BU_SG_REL_ PDCF SG_ 151 HCU_FrontWheelMaxBrakeRegTorque 100;
BA_REL_ "GenSigTimeoutTime" BU_SG_REL_ PDCF SG_ 151 HCU_FrontWheelMaxBrakeRegTorqSt 100;
BA_REL_ "GenSigTimeoutTime" BU_SG_REL_ PDCF SG_ 151 HCU_FrontWheelBrakeRegTorque 100;
BA_REL_ "GenSigTimeoutTime" BU_SG_REL_ PDCF SG_ 151 HCU_FrontWheelBrakeRegTorqueSt 100;
BA_REL_ "GenSigTimeoutTime" BU_SG_REL_ PDCF SG_ 151 HCU_MCU2TMSpeed 100;
BA_REL_ "GenSigTimeoutTime" BU_SG_REL_ PDCF SG_ 151 HCU_RearWheelActTorque 100;
BA_REL_ "GenSigTimeoutTime" BU_SG_REL_ PDCF SG_ 151 HCU_RearWheelActTorqueSt 100;
BA_REL_ "GenSigTimeoutTime" BU_SG_REL_ PDCF SG_ 151 HCU_RearWheelMaxDriveTorque 100;
BA_REL_ "GenSigTimeoutTime" BU_SG_REL_ PDCF SG_ 151 HCU_RearWheelMaxDriveTorqueSt 100;
BA_REL_ "GenSigTimeoutTime" BU_SG_REL_ PDCF SG_ 151 HCU_RearWheelMaxBrakeRegTorque 100;
BA_REL_ "GenSigTimeoutTime" BU_SG_REL_ PDCF SG_ 151 HCU_RearWheelMaxBrakeRegTorqSt 100;
BA_REL_ "GenSigTimeoutTime" BU_SG_REL_ PDCF SG_ 151 HCU_RearWheelBrakeRegTorque 100;
BA_REL_ "GenSigTimeoutTime" BU_SG_REL_ PDCF SG_ 151 HCU_RearWheelBrakeRegTorqueSt 100;
BA_REL_ "GenSigTimeoutTime" BU_SG_REL_ PDCF SG_ 151 LiveCounter_HCU_2_10 100;
BA_REL_ "GenSigTimeoutTime" BU_SG_REL_ PDCF SG_ 290 Checksum_HCU_2_12 200;
BA_REL_ "GenSigTimeoutTime" BU_SG_REL_ PDCF SG_ 290 HCU2_LeverInfo 200;
BA_REL_ "GenSigTimeoutTime" BU_SG_REL_ PDCF SG_ 290 HCU_HighVoltageStatus 200;
BA_REL_ "GenSigTimeoutTime" BU_SG_REL_ PDCF SG_ 290 HCU_AutoParkingResponse_HPA 200;
BA_REL_ "GenSigTimeoutTime" BU_SG_REL_ PDCF SG_ 290 HCU_AutoParkingResponse_AVP 200;
BA_REL_ "GenSigTimeoutTime" BU_SG_REL_ PDCF SG_ 290 HCU_AutoParkingResponse_APA 200;
BA_REL_ "GenSigTimeoutTime" BU_SG_REL_ PDCF SG_ 290 HCU_AutoParkingResponse_RPA 200;
BA_REL_ "GenSigTimeoutTime" BU_SG_REL_ PDCF SG_ 290 HCU_CapabilitySt_AutoParking 200;
BA_REL_ "GenSigTimeoutTime" BU_SG_REL_ PDCF SG_ 290 HCU_PowertrainErrorSt 200;
BA_REL_ "GenSigTimeoutTime" BU_SG_REL_ PDCF SG_ 290 HCU_PowertrainWorkSt 200;
BA_REL_ "GenSigTimeoutTime" BU_SG_REL_ PDCF SG_ 290 HCU_MCU1TorqueCtrlAvailableSt 200;
BA_REL_ "GenSigTimeoutTime" BU_SG_REL_ PDCF SG_ 290 HCU_MCU2TorqueCtrlAvailableSt 200;
BA_REL_ "GenSigTimeoutTime" BU_SG_REL_ PDCF SG_ 290 Livecounter_HCU_2_12 200;
BA_REL_ "GenSigTimeoutTime" BU_SG_REL_ PDCF SG_ 146 Checksum_HCU_2_2 100;
BA_REL_ "GenSigTimeoutTime" BU_SG_REL_ PDCF SG_ 146 HCU_EPBLeverRequest 100;
BA_REL_ "GenSigTimeoutTime" BU_SG_REL_ PDCF SG_ 146 HCU_AccelerationPedalPosition 100;
BA_REL_ "GenSigTimeoutTime" BU_SG_REL_ PDCF SG_ 146 HCU_CalcAccelerationPedalPositio 100;
BA_REL_ "GenSigTimeoutTime" BU_SG_REL_ PDCF SG_ 146 HCU_AccelerationPedalOverride 100;
BA_REL_ "GenSigTimeoutTime" BU_SG_REL_ PDCF SG_ 146 HCU_KickdownReq 100;
BA_REL_ "GenSigTimeoutTime" BU_SG_REL_ PDCF SG_ 146 LiveCounter_HCU_2_2 100;
BA_REL_ "GenSigTimeoutTime" BU_SG_REL_ PDCF SG_ 264 Checksum_HCU_2_4 100;
BA_REL_ "GenSigTimeoutTime" BU_SG_REL_ PDCF SG_ 264 HCU_DriverTorq_FrontWheel 100;
BA_REL_ "GenSigTimeoutTime" BU_SG_REL_ PDCF SG_ 264 HCU_AutoDrivingResponseSt_L12 100;
BA_REL_ "GenSigTimeoutTime" BU_SG_REL_ PDCF SG_ 264 HCU_AutoDrivingResponseSt_L3 100;
BA_REL_ "GenSigTimeoutTime" BU_SG_REL_ PDCF SG_ 264 HCU_CruiseControlSt 100;
BA_REL_ "GenSigTimeoutTime" BU_SG_REL_ PDCF SG_ 264 HCU_CapabilitySt_AutoDriving 100;
BA_REL_ "GenSigTimeoutTime" BU_SG_REL_ PDCF SG_ 264 HCU_DriverTorq_RearWheel 100;
BA_REL_ "GenSigTimeoutTime" BU_SG_REL_ PDCF SG_ 264 HCU_GradientAccelerationPedal 100;
BA_REL_ "GenSigTimeoutTime" BU_SG_REL_ PDCF SG_ 264 LiveCounter_HCU_2_4 100;
BA_REL_ "GenSigTimeoutTime" BU_SG_REL_ PDCF SG_ 147 HCU_SlipContrlIntervention_Front 100;
BA_REL_ "GenSigTimeoutTime" BU_SG_REL_ PDCF SG_ 147 HCU_SlipContrlIntervention_RearA 100;
BA_REL_ "GenSigTimeoutTime" BU_SG_REL_ PDCF SG_ 147 HCU_SlopeContrlIntervention 100;
BA_REL_ "GenSigTimeoutTime" BU_SG_REL_ PDCF SG_ 147 HCU_YawRateContrlIntervention 100;
BA_REL_ "GenSigTimeoutTime" BU_SG_REL_ PDCF SG_ 147 HCU_EVReady 100;
BA_REL_ "GenSigTimeoutTime" BU_SG_REL_ PDCF SG_ 1376 SECOC_TripCounter 300000;
BA_REL_ "GenSigTimeoutTime" BU_SG_REL_ PDCF SG_ 1376 SECOC_ResetCounter 300000;
BA_REL_ "GenSigTimeoutTime" BU_SG_REL_ PDCF SG_ 1376 SECOC_Authenticator 300000;
BA_REL_ "GenSigTimeoutTime" BU_SG_REL_ PDCF SG_ 280 Checksum_VDC_1 200;
BA_REL_ "GenSigTimeoutTime" BU_SG_REL_ PDCF SG_ 280 VDC_AutoDrivingReq_L12 200;
BA_REL_ "GenSigTimeoutTime" BU_SG_REL_ PDCF SG_ 280 VDC_DecelerationReqEnable_AEB 200;
BA_REL_ "GenSigTimeoutTime" BU_SG_REL_ PDCF SG_ 280 VDC_SteeringTorqueRequestSign 200;
BA_REL_ "GenSigTimeoutTime" BU_SG_REL_ PDCF SG_ 280 VDC_SteeringTorqueReqSt 200;
BA_REL_ "GenSigTimeoutTime" BU_SG_REL_ PDCF SG_ 280 VDC_Intervention_LKA 200;
BA_REL_ "GenSigTimeoutTime" BU_SG_REL_ PDCF SG_ 280 VDC_WorkingSt_LKA 200;
BA_REL_ "GenSigTimeoutTime" BU_SG_REL_ PDCF SG_ 280 VDC_ErrorSt_LKA 200;
BA_REL_ "GenSigTimeoutTime" BU_SG_REL_ PDCF SG_ 280 VDC_AccelerationPedalOverride 200;
BA_REL_ "GenSigTimeoutTime" BU_SG_REL_ PDCF SG_ 280 VDC_WorkingSt_AEB_L12 200;
BA_REL_ "GenSigTimeoutTime" BU_SG_REL_ PDCF SG_ 280 VDC_ErrorSt_AEB_L12 200;
BA_REL_ "GenSigTimeoutTime" BU_SG_REL_ PDCF SG_ 280 VDC_ErrorSt_ACC_L12 200;
BA_REL_ "GenSigTimeoutTime" BU_SG_REL_ PDCF SG_ 280 VDC_SpeedChangeRequest_L12 200;
BA_REL_ "GenSigTimeoutTime" BU_SG_REL_ PDCF SG_ 280 VDC_DriveAwayReq_L12 200;
BA_REL_ "GenSigTimeoutTime" BU_SG_REL_ PDCF SG_ 280 VDC_StopReq_L12 200;
BA_REL_ "GenSigTimeoutTime" BU_SG_REL_ PDCF SG_ 280 VDC_WorkingSt_ACC_L12 200;
BA_REL_ "GenSigTimeoutTime" BU_SG_REL_ PDCF SG_ 280 VDC_TakeOverTip_LCA 200;
BA_REL_ "GenSigTimeoutTime" BU_SG_REL_ PDCF SG_ 280 VDC_ABPReq_L12 200;
BA_REL_ "GenSigTimeoutTime" BU_SG_REL_ PDCF SG_ 280 VDC_AWBReq_L12 200;
BA_REL_ "GenSigTimeoutTime" BU_SG_REL_ PDCF SG_ 280 VDC_AWBlevel_L12 200;
BA_REL_ "GenSigTimeoutTime" BU_SG_REL_ PDCF SG_ 280 VDC_CruiseModeFunctionInd 200;
BA_REL_ "GenSigTimeoutTime" BU_SG_REL_ PDCF SG_ 280 VDC_BrakeModeReq_L12 200;
BA_REL_ "GenSigTimeoutTime" BU_SG_REL_ PDCF SG_ 280 VDC_DrivedownModeReq_L12 200;
BA_REL_ "GenSigTimeoutTime" BU_SG_REL_ PDCF SG_ 280 VDC_SecureRequest_L12 200;
BA_REL_ "GenSigTimeoutTime" BU_SG_REL_ PDCF SG_ 280 VDC_AEBSensitivity_L12 200;
BA_REL_ "GenSigTimeoutTime" BU_SG_REL_ PDCF SG_ 280 VDC_ErrorSt_LCA 200;
BA_REL_ "GenSigTimeoutTime" BU_SG_REL_ PDCF SG_ 280 VDC_AutoDrivingReq 200;
BA_REL_ "GenSigTimeoutTime" BU_SG_REL_ PDCF SG_ 280 VDC_AutoDrivingLevel 200;
BA_REL_ "GenSigTimeoutTime" BU_SG_REL_ PDCF SG_ 280 VDC_HandsOffTip_LCA 200;
BA_REL_ "GenSigTimeoutTime" BU_SG_REL_ PDCF SG_ 280 VDC_ErrorSt_SACC 200;
BA_REL_ "GenSigTimeoutTime" BU_SG_REL_ PDCF SG_ 280 VDC_DecelerationReq_AEB 200;
BA_REL_ "GenSigTimeoutTime" BU_SG_REL_ PDCF SG_ 280 VDC_WorkingSt_LCA 200;
BA_REL_ "GenSigTimeoutTime" BU_SG_REL_ PDCF SG_ 280 VDC_ErrorSt_VDC 200;
BA_REL_ "GenSigTimeoutTime" BU_SG_REL_ PDCF SG_ 280 VDC_SteeringTorqueRequest 200;
BA_REL_ "GenSigTimeoutTime" BU_SG_REL_ PDCF SG_ 280 VDC_AutoDrivingModeReq 200;
BA_REL_ "GenSigTimeoutTime" BU_SG_REL_ PDCF SG_ 280 VDC_WorkingSt_SACC 200;
BA_REL_ "GenSigTimeoutTime" BU_SG_REL_ PDCF SG_ 280 VDC_WorkingSt_DCLC 200;
BA_REL_ "GenSigTimeoutTime" BU_SG_REL_ PDCF SG_ 280 VDC_ErrorSt_EMA 200;
BA_REL_ "GenSigTimeoutTime" BU_SG_REL_ PDCF SG_ 280 VDC_WorkingSt_EMA 200;
BA_REL_ "GenSigTimeoutTime" BU_SG_REL_ PDCF SG_ 280 VDC_SteeringWheelAngleRequest 200;
BA_REL_ "GenSigTimeoutTime" BU_SG_REL_ PDCF SG_ 280 SACC_RearWheelAngleRequestSt 200;
BA_REL_ "GenSigTimeoutTime" BU_SG_REL_ PDCF SG_ 280 VDC_SteeringWheelAngleSignReques 200;
BA_REL_ "GenSigTimeoutTime" BU_SG_REL_ PDCF SG_ 280 VDC_SteeringWheelAngleControlReq 200;
BA_REL_ "GenSigTimeoutTime" BU_SG_REL_ PDCF SG_ 280 SACC_RearWheelReturnReq 200;
BA_REL_ "GenSigTimeoutTime" BU_SG_REL_ PDCF SG_ 280 LKA_RearWheelAngleRequestSt 200;
BA_REL_ "GenSigTimeoutTime" BU_SG_REL_ PDCF SG_ 280 LKA_RearWheelReturnReq 200;
BA_REL_ "GenSigTimeoutTime" BU_SG_REL_ PDCF SG_ 280 VDC_AutoDrivingModeReq_EMA 200;
BA_REL_ "GenSigTimeoutTime" BU_SG_REL_ PDCF SG_ 280 VDC_SteeringWheelBlendingGain 200;
BA_REL_ "GenSigTimeoutTime" BU_SG_REL_ PDCF SG_ 280 VDC_SteeringMaxTorqueRequest 200;
BA_REL_ "GenSigTimeoutTime" BU_SG_REL_ PDCF SG_ 280 SACC_RearWheelAngleRequest 200;
BA_REL_ "GenSigTimeoutTime" BU_SG_REL_ PDCF SG_ 280 LKA_RearWheelAngleRequest 200;
BA_REL_ "GenSigTimeoutTime" BU_SG_REL_ PDCF SG_ 280 VDC_WorkingSt_FCW 200;
BA_REL_ "GenSigTimeoutTime" BU_SG_REL_ PDCF SG_ 280 VDC_ErrorSt_FCW 200;
BA_REL_ "GenSigTimeoutTime" BU_SG_REL_ PDCF SG_ 280 LiveCounter_VDC_1 200;
BA_REL_ "GenSigTimeoutTime" BU_SG_REL_ PDCF SG_ 282 Checksum_HAD_3 200;
BA_REL_ "GenSigTimeoutTime" BU_SG_REL_ PDCF SG_ 282 HAD_AutoDrivingReq_L3 200;
BA_REL_ "GenSigTimeoutTime" BU_SG_REL_ PDCF SG_ 282 HAD_SpeedChangeRequest_L3 200;
BA_REL_ "GenSigTimeoutTime" BU_SG_REL_ PDCF SG_ 282 HAD_TimeGapSetting 200;
BA_REL_ "GenSigTimeoutTime" BU_SG_REL_ PDCF SG_ 282 NOP_RearWheelAngleRequest 200;
BA_REL_ "GenSigTimeoutTime" BU_SG_REL_ PDCF SG_ 282 NOP_RearWheelAngleRequestSt 200;
BA_REL_ "GenSigTimeoutTime" BU_SG_REL_ PDCF SG_ 282 NOP_RearWheelReturnReq 200;
BA_REL_ "GenSigTimeoutTime" BU_SG_REL_ PDCF SG_ 282 HAD_ObjectDetection 200;
BA_REL_ "GenSigTimeoutTime" BU_SG_REL_ PDCF SG_ 282 HAD_TakeOverReq 200;
BA_REL_ "GenSigTimeoutTime" BU_SG_REL_ PDCF SG_ 282 HAD_CruiseSpeedSetting_ACC 200;
BA_REL_ "GenSigTimeoutTime" BU_SG_REL_ PDCF SG_ 282 HAD_SysTextinfo 200;
BA_REL_ "GenSigTimeoutTime" BU_SG_REL_ PDCF SG_ 282 HAD_LDWModeInd 200;
BA_REL_ "GenSigTimeoutTime" BU_SG_REL_ PDCF SG_ 282 HAD_AutoLightModeReq 200;
BA_REL_ "GenSigTimeoutTime" BU_SG_REL_ PDCF SG_ 282 HAD_HazardWarningLampRequest 200;
BA_REL_ "GenSigTimeoutTime" BU_SG_REL_ PDCF SG_ 282 HAD_WorkingSt_LDW 200;
BA_REL_ "GenSigTimeoutTime" BU_SG_REL_ PDCF SG_ 282 HAD_WarningCmd_LDW 200;
BA_REL_ "GenSigTimeoutTime" BU_SG_REL_ PDCF SG_ 282 HAD_LDWLaneDetectSt 200;
BA_REL_ "GenSigTimeoutTime" BU_SG_REL_ PDCF SG_ 282 HAD_SensitivityInd_LDW 200;
BA_REL_ "GenSigTimeoutTime" BU_SG_REL_ PDCF SG_ 282 HAD_ErrorSt_LDW 200;
BA_REL_ "GenSigTimeoutTime" BU_SG_REL_ PDCF SG_ 282 HAD_WorkingSt_FCW 200;
BA_REL_ "GenSigTimeoutTime" BU_SG_REL_ PDCF SG_ 282 HAD_DriveAwayReq_L3 200;
BA_REL_ "GenSigTimeoutTime" BU_SG_REL_ PDCF SG_ 282 HAD_StopReq_L3 200;
BA_REL_ "GenSigTimeoutTime" BU_SG_REL_ PDCF SG_ 282 HAD_AccelerationPedalOverride 200;
BA_REL_ "GenSigTimeoutTime" BU_SG_REL_ PDCF SG_ 282 HAD_SensitivityInd_FCW 200;
BA_REL_ "GenSigTimeoutTime" BU_SG_REL_ PDCF SG_ 282 HAD_FCWModeInd 200;
BA_REL_ "GenSigTimeoutTime" BU_SG_REL_ PDCF SG_ 282 HAD_WiperAutoLeverReq 200;
BA_REL_ "GenSigTimeoutTime" BU_SG_REL_ PDCF SG_ 282 HAD_VASFunctionInd 200;
BA_REL_ "GenSigTimeoutTime" BU_SG_REL_ PDCF SG_ 282 HAD_SACCNotSatisfiedCondition 200;
BA_REL_ "GenSigTimeoutTime" BU_SG_REL_ PDCF SG_ 282 HAD_LDW_SpeechControlFeedback 200;
BA_REL_ "GenSigTimeoutTime" BU_SG_REL_ PDCF SG_ 282 HAD_IFCSystemError 200;
BA_REL_ "GenSigTimeoutTime" BU_SG_REL_ PDCF SG_ 282 HAD_IFCCalibrationStatus 200;
BA_REL_ "GenSigTimeoutTime" BU_SG_REL_ PDCF SG_ 282 HAD_WarningCmd_VAS 200;
BA_REL_ "GenSigTimeoutTime" BU_SG_REL_ PDCF SG_ 282 HAD_LeftTurningLampRequest 200;
BA_REL_ "GenSigTimeoutTime" BU_SG_REL_ PDCF SG_ 282 HAD_RightTurningLampRequest 200;
BA_REL_ "GenSigTimeoutTime" BU_SG_REL_ PDCF SG_ 282 HAD_ValetModeStatus 200;
BA_REL_ "GenSigTimeoutTime" BU_SG_REL_ PDCF SG_ 282 HAD_BrakeModeReq_L3 200;
BA_REL_ "GenSigTimeoutTime" BU_SG_REL_ PDCF SG_ 282 HAD_DrivedownModeReq_L3 200;
BA_REL_ "GenSigTimeoutTime" BU_SG_REL_ PDCF SG_ 282 HAD_SecureRequest_L3 200;
BA_REL_ "GenSigTimeoutTime" BU_SG_REL_ PDCF SG_ 282 HAD_ErrorSt_AutoDriving_L3 200;
BA_REL_ "GenSigTimeoutTime" BU_SG_REL_ PDCF SG_ 282 HAD_WorkingSt_NOP 200;
BA_REL_ "GenSigTimeoutTime" BU_SG_REL_ PDCF SG_ 282 HAD_ErrorSt_NOP 200;
BA_REL_ "GenSigTimeoutTime" BU_SG_REL_ PDCF SG_ 282 HAD_ErrorSt_HAD 200;
BA_REL_ "GenSigTimeoutTime" BU_SG_REL_ PDCF SG_ 282 HAD_AutoDrivingModeReq_NOP 200;
BA_REL_ "GenSigTimeoutTime" BU_SG_REL_ PDCF SG_ 282 HAD_AutoDrivingModeReq_NGP 200;
BA_REL_ "GenSigTimeoutTime" BU_SG_REL_ PDCF SG_ 282 HAD_SteeringWheelBlendingGain 200;
BA_REL_ "GenSigTimeoutTime" BU_SG_REL_ PDCF SG_ 282 HAD_SteeringWheelAngleRequest 200;
BA_REL_ "GenSigTimeoutTime" BU_SG_REL_ PDCF SG_ 282 HAD_SteeringWheelAngleSignReques 200;
BA_REL_ "GenSigTimeoutTime" BU_SG_REL_ PDCF SG_ 282 HAD_SteeringWheelAngleControlReq 200;
BA_REL_ "GenSigTimeoutTime" BU_SG_REL_ PDCF SG_ 282 HAD_WorkingSt_NGP 200;
BA_REL_ "GenSigTimeoutTime" BU_SG_REL_ PDCF SG_ 282 HAD_ErrorSt_NGP 200;
BA_REL_ "GenSigTimeoutTime" BU_SG_REL_ PDCF SG_ 282 LiveCounter_HAD_3 200;
BA_REL_ "GenSigTimeoutTime" BU_SG_REL_ PDCF SG_ 512 CrashInfo 1000;
BA_REL_ "GenSigTimeoutTime" BU_SG_REL_ PDCF SG_ 512 SysSt_ACU 1000;
BA_REL_ "GenSigTimeoutTime" BU_SG_REL_ PDCF SG_ 586 DoorSt_FL 1000;
BA_REL_ "GenSigTimeoutTime" BU_SG_REL_ PDCF SG_ 580 SeatBeltSt_DSCU 1000;
BA_REL_ "GenSigTimeoutTime" BU_SG_REL_ PDCF SG_ 288 EGSM_ParkButton 200;
BA_REL_ "GenSigTimeoutTime" BU_SG_REL_ PDCF SG_ 308 Checksum_PDCM_YRS 200;
BA_REL_ "GenSigTimeoutTime" BU_SG_REL_ PDCF SG_ 308 YawRate 200;
BA_REL_ "GenSigTimeoutTime" BU_SG_REL_ PDCF SG_ 308 YRSSt 200;
BA_REL_ "GenSigTimeoutTime" BU_SG_REL_ PDCF SG_ 308 Acceleration_X 200;
BA_REL_ "GenSigTimeoutTime" BU_SG_REL_ PDCF SG_ 308 Acceleration_Y 200;
BA_REL_ "GenSigTimeoutTime" BU_SG_REL_ PDCF SG_ 308 ErrorSt_YRS 200;
BA_REL_ "GenSigTimeoutTime" BU_SG_REL_ PDCF SG_ 308 LiveCounter_PDCM_YRS 200;
BA_REL_ "GenSigTimeoutTime" BU_SG_REL_ PDCF SG_ 588 DoorSt_FR 1000;
BA_REL_ "GenSigTimeoutTime" BU_SG_REL_ PDCF SG_ 292 Checksum_YAW_1 100;
BA_REL_ "GenSigTimeoutTime" BU_SG_REL_ PDCF SG_ 292 Acceleration_X_ACU 100;
BA_REL_ "GenSigTimeoutTime" BU_SG_REL_ PDCF SG_ 292 Acceleration_Y_ACU 100;
BA_REL_ "GenSigTimeoutTime" BU_SG_REL_ PDCF SG_ 292 YawRate_ACU 100;
BA_REL_ "GenSigTimeoutTime" BU_SG_REL_ PDCF SG_ 292 LatSensorSt 100;
BA_REL_ "GenSigTimeoutTime" BU_SG_REL_ PDCF SG_ 292 LgtSensorSt 100;
BA_REL_ "GenSigTimeoutTime" BU_SG_REL_ PDCF SG_ 292 YRSCalibrateSt_ACU 100;
BA_REL_ "GenSigTimeoutTime" BU_SG_REL_ PDCF SG_ 292 YRSSt_ACU 100;
BA_REL_ "GenSigTimeoutTime" BU_SG_REL_ PDCF SG_ 292 LiveCounter_YAW_1 100;
BA_REL_ "GenSigTimeoutTime" BU_SG_REL_ PDCF SG_ 640 EPBFunctionSet 1000;
VAL_ 169 RBU_WheelSpeed_FL 32767 "SNA" ;
VAL_ 169 RBU_WheelSpeed_FR 32767 "SNA" ;
VAL_ 169 RBU_WheelSpeed_RL 32767 "SNA" ;
VAL_ 169 RBU_WheelSpeed_RR 32767 "SNA" ;
VAL_ 169 RBU_ErrorSt_SBS 1 "Error" 0 "No_Error" ;
VAL_ 169 RBU_Intervention_SBS 1 "Intervention" 0 "No_Intervention" ;
VAL_ 169 RBU_EPBAvailableSt_L3 1 "Not Available" 0 "Available" ;
VAL_ 169 RBU_UsedChannel_L3 3 "HAD2Com1" 2 "HAD1Com2" 1 "HAD1Com1" 0 "NoChannel" ;
VAL_ 169 RBU_ControllerReleaseSt_L3 1 "Release" 0 "NotRelease" ;
VAL_ 169 RBU_SuspendStatusByDriver_L3 3 "Not_Used" 2 "SuspendByDriverPropulsion" 1 "SuspendByDriverBrake" 0 "No Suspend" ;
VAL_ 169 RBU_BrakePedalStatus_Q 3 "Not_Used" 2 "Full" 1 "Fault" 0 "NotInitialized" ;
VAL_ 169 RBU_BrakePedalStatus 3 "Error" 2 "Not_Used" 1 "Actuated" 0 "Not_Actuated" ;
VAL_ 169 RBU_VLCSt 3 "Not_Used" 2 "Active_L3" 1 "Active_L12" 0 "Inactivce" ;
VAL_ 169 RBU_VMC_Error_L3 7 "Not_Used" 6 "Not_Used" 5 "Not_Used" 4 "Available" 3 "AvailableWithSituationIssue" 2 "AvailableWithFault" 1 "NotAvailableBySituation" 0 "NotAvailable" ;
VAL_ 169 RBU_DrivingDirection 3 "Undefined" 2 "Backward" 1 "Forward" 0 "Stop" ;
VAL_ 169 RBU_VehicleSpeed 32767 "SNA" ;
VAL_ 169 RBU_TargetGearReq_VMC_1 7 "Invalid" 6 "Not_Used" 5 "Not_Used" 4 "Target_gear_D" 3 "Target_gear_N" 2 "Target_gear_R" 1 "Target_gear_P" 0 "No_Request" ;
VAL_ 169 RBU_TargetGearReqEnable_VMC_1 1 "Enable" 0 "Not enable" ;
VAL_ 169 RBU_VehicleStandstillSt 1 "The_vehicle_is_in_standstill." 0 "The_vehicle_is_not__in_standstill." ;
VAL_ 169 RBU_BrakeLightCtrlCmd 1 "Illuminate" 0 "Not_illuminate" ;
VAL_ 169 RBUIBC_DriveMain2BackupState 15 "Not_Used" 14 "Not_Used" 13 "Not_Used" 12 "Not_Used" 11 "Deactivation_pending " 10 "Activated_RedundancyLost" 9 "Activated_FailOperation" 8 "Activated_FullAvailable" 7 "Activation_PendingFailOperation" 6 "Activation_PendingRedundancyLost" 5 "Activation_Pending " 4 "Activation_Preparation" 3 "NotActivated_FullAvailable" 2 "NotAvailable_permanent" 1 "NotAvailable_NotReleased " 0 "NotAvailable_temporary " ;
VAL_ 169 RBUIBC_StopMain2BackupState 7 "Not_Used" 6 "Not_Used" 5 "Not_Used" 4 "Not_Used" 3 "Deactivation_pending " 2 "Activated_RedundancyLost" 1 "Activated_FailOperation" 0 "Activated_FullAvailable" 7 "Activation_PendingFailOperation" 6 "Activation_PendingRedundancyLost" 5 "Activation_Pending " 4 "Activation_Preparation" 3 "NotActivated_FullAvailable" 2 "NotAvailable_permanent" 1 "NotAvailable_NotReleased " 0 "NotAvailable_temporary " ;
VAL_ 169 RBUIPB_RBUSelfTestInfo 15 "Not_Used" 14 "Not_Used" 13 "Not_Used" 12 "Not_Used" 11 "Not_Used" 10 "Not_Used" 9 "Not_Used" 8 "Not_Used" 7 "Not_Used" 6 "Not_Used" 5 "RBUSelfTest_Aborted " 4 "IBC_RBUSelfTest_InProgress " 3 "RBUSelfTest_Prepared" 2 "RBUSelfTest_Requested" 1 "RBUSelfTest_PreCondMet" 0 "RBUSelfTest_PreCondNotMet " ;
VAL_ 169 RBUIBC_VariantInfo 1 "Variant2" 0 "Variant1" ;
VAL_ 190 SteerRearControlAngleReq_RVA 4095 "SNA" ;
VAL_ 190 SteerRearControlSt_RVA 3 "Error" 2 "Request" 1 "Not Request" 0 "Initial" ;
VAL_ 190 WorkingSt_RVA 7 "Invalid value" 6 "Reserved" 5 "LKA Control" 4 "NOP Control" 3 "SACC Control" 2 "APA Control" 1 "IBC Control" 0 "Not Control" ;
VAL_ 190 BehaviorMode_RVA 7 "Invalid value" 6 "Reserved" 5 "Reserved" 4 "Fail" 3 "Temporary inhabit" 2 "Active" 1 "Standby" 0 "Initial" ;
VAL_ 190 ErrorSt_RVA 3 "Reserved" 2 "Critical Error" 1 "General Error" 0 "No Error" ;
VAL_ 190 IBCControlAvailable_RVA 1 "Availbale" 0 "Not Available" ;
VAL_ 190 APAControlSt_RVA 1 "Enable" 0 "Disable" ;
VAL_ 190 APAAbortFeedback_RVA 31 "Reserved" 30 "Reserved" 29 "Reserved" 28 "Reserved" 27 "Reserved" 26 "Reserved" 25 "Reserved" 24 "Reserved" 23 "Reserved" 22 "Reserved" 21 "Reserved" 20 "Reserved" 19 "Reserved" 18 "Reserved" 17 "Reserved" 16 "Reserved" 15 "Reserved" 14 "Reserved" 13 "Reserved" 12 "Reserved" 11 "RWS internal failure with limited steering assistance" 10 "RWS system critical failure no steering assistance" 9 "CAN Bus Off" 8 "Rear Steering Wheel Angle exceeds limits" 7 "RWS control active received without handshaking" 6 "RVA control Req received when in control" 5 "Vehicle Speed exceeds limits when in control" 4 "RVA Handshaking time out£®t2£©" 3 "APA System signal invalid or time out" 2 "Vehicle Speed invalid or time out" 1 "Vehicle Speed exceeds limits before control" 0 "No driving interuption" ;
VAL_ 190 SACCControlSt_RVA 3 "Occupy" 2 "Active" 1 "Enable" 0 "Disable" ;
VAL_ 190 LKAControlSt_RVA 3 "Occupy" 2 "Active" 1 "Enable" 0 "Disable" ;
VAL_ 190 NOPControlSt_RVA 3 "Occupy" 2 "Active" 1 "Enable" 0 "Disable" ;
VAL_ 188 RearWheelAngle_QF 3 "Valid" 2 "Inaccurate" 1 "Initial" 0 "Invalid" ;
VAL_ 188 WorkingSt_RWS 7 "Diagnosis" 6 "Inactive" 5 "Ramping" 4 "Yellow" 3 "Red" 2 "Normal" 1 "Pending" 0 "Initialisation" ;
VAL_ 188 ErrorSt_RWS 3 "Reserved" 2 "Critical Error" 1 "General Error" 0 "No Error" ;
VAL_ 785 WiperBrushAngle 255 "SNA" ;
VAL_ 785 WiperBrushSpeed 63 "SNA" ;
VAL_ 785 WiperMotorSt 1 "Active" 0 "Inavtive" ;
VAL_ 785 WiperParkPosition 1 "On" 0 "Off" ;
VAL_ 785 ServicePosition_WMM 1 "On" 0 "Off" ;
VAL_ 785 WiperTurnningPosition 1 "On" 0 "Off" ;
VAL_ 785 LINError_WMM 1 "Error" 0 "No error" ;
VAL_ 785 WMMFaultSt 1 "Fault" 0 "No fault" ;
VAL_ 560 TurningLightCmd_Left 1 "On" 0 "Off" ;
VAL_ 560 TurningLightCmd_Right 1 "On" 0 "Off" ;
VAL_ 560 FlowTurningLightCmd_Left 1 "On" 0 "Off" ;
VAL_ 560 FlowTurningLightCmd_Right 1 "On" 0 "Off" ;
VAL_ 562 PowerMode 15 "Invalid value" 14 "Reserved" 13 "Reserved" 12 "Reserved" 11 "Reserved" 10 "Reserved" 9 "Reserved" 8 "Reserved" 7 "Reserved" 6 "Reserved" 5 "Reserved" 4 "IgnitionOn " 3 "Reserved" 2 "Reserved" 1 "Reserved" 0 "Off" ;
VAL_ 567 PositionLightCmd_FL 1 "On" 0 "Off" ;
VAL_ 567 PositionLightCmd_FR 1 "On" 0 "Off" ;
VAL_ 567 DayRunningLightCmd_Left 1 "On" 0 "Off" ;
VAL_ 567 DayRunningLightCmd_Right 1 "On" 0 "Off" ;
VAL_ 567 HighBeamCmd_Left 1 "On" 0 "Off" ;
VAL_ 567 HighBeamCmd_Right 1 "On" 0 "Off" ;
VAL_ 567 FrontFogCmd_Left 1 "On" 0 "Off" ;
VAL_ 567 FrontFogCmd_Right 1 "On" 0 "Off" ;
VAL_ 567 FlowDayRunningLightCmd_Left 1 "On" 0 "Off" ;
VAL_ 567 FlowDayRunningLightCmd_Right 1 "On" 0 "Off" ;
VAL_ 567 ADS_LightCmd 1 "On" 0 "Off" ;
VAL_ 567 CeremonyScenarioSet 7 "Reserved" 6 "Reserved" 5 "Reserved" 4 "Reserved" 3 "Reserved" 2 "Lock the car" 1 "Unlock the car" 0 "Inactive" ;
VAL_ 567 CornerLampCmd_Right 1 "On" 0 "Off" ;
VAL_ 567 CornerLampCmd_Left 1 "On" 0 "Off" ;
VAL_ 567 CeremonyModeSet 7 "Reserved" 6 "Mode 5" 5 "Mode 4" 4 "Mode 3" 3 "Mode 2" 2 "Mode 1" 1 "Off" 0 "Inactive" ;
VAL_ 567 CeremonySyncCounter 4095 "SNA" ;
VAL_ 497 LowBeamCmd_Left 1 "On" 0 "Off" ;
VAL_ 497 LowBeamCmd_Right 1 "On" 0 "Off" ;
VAL_ 532 DMS_ESCModeChangeCmd 15 "Reserved" 14 "Reserved" 13 "Reserved" 12 "Reserved" 11 "Reserved" 10 "Reserved" 9 "Reserved" 8 "Extreme" 7 "Sport" 6 "Sand" 5 "MUD_Ruts" 4 "Off_road" 3 "Snow" 2 "Eco" 1 "Auto" 0 "Inactive" ;
VAL_ 532 DMS_EPSModeChangeCmd 3 "Comfort" 2 "Sport" 1 "Auto" 0 "Inactive" ;
VAL_ 784 WiperSwitch 7 "Invalid value" 6 "Reserved" 5 "Reserved" 4 "HighSpeed" 3 "LowSpeed" 2 "IntermitOrAuto" 1 "MIST" 0 "Off" ;
VAL_ 784 WashSwitch_FrontWindow 1 "On" 0 "Off" ;
VAL_ 784 WiperSwitch_SensitiveLevel 15 "Error" 14 "Reserved" 13 "IntervalStep 4" 12 "Reserved" 11 "Reserved" 10 "Reserved" 9 "IntervalStep 3" 8 "Reserved" 7 "Reserved" 6 "Reserved" 5 "IntervalStep 2" 4 "Reserved" 3 "Reserved" 2 "Reserved" 1 "IntervalStep 1" 0 "Inactive" ;
VAL_ 784 VehicleSpeed_WMM 255 "SNA" ;
VAL_ 784 AmbientTemp_WMM 255 "SNA" ;
VAL_ 784 AutoWiperSpeed 7 "60 times/min" 6 "57 times/min" 5 "54 times/min" 4 "51 times/min" 3 "48 times/min" 2 "45 times/min" 1 "42 times/min" 0 "No wipe" ;
VAL_ 784 Splash_WMM 1 "On" 0 "Off" ;
VAL_ 784 RainLightSensorStatus 1 "Active" 0 "Inactive" ;
VAL_ 784 EngineHoodSt 1 "Open" 0 "Close" ;
VAL_ 784 ServicePositionCmd 1 "Active" 0 "Inactive" ;
VAL_ 784 IgnitionState 1 "On" 0 "Off" ;
VAL_ 784 CrankingState 1 "Cranking" 0 "No cranking" ;
VAL_ 890 SignLamp1_Cmd 1 "On" 0 "Off" ;
VAL_ 890 SignLamp2_Cmd 1 "On" 0 "Off" ;
VAL_ 688 VDC_IgnitionOffTime 4095 "SNA" ;
VAL_ 688 VDC_RemoteVehicleMode 1 "Remote_Mode" 0 "Normal_Mode" ;
VAL_ 688 VDC_OTAMode 7 "Reserved" 6 "Reserved" 5 "Reserved" 4 "Reserved" 3 "Reserved" 2 "Reserved" 1 "OTA_Mode" 0 "Normal_Mode" ;
VAL_ 688 VDC_VehicleMode 15 "Invalid_value" 14 "Reserved" 13 "Reserved" 12 "Reserved" 11 "Reserved" 10 "Reserved" 9 "Reserved" 8 "Reserved" 7 "Reserved" 6 "Reserved" 5 "Reserved" 4 "Storage_Mode" 3 "Normal_Mode" 2 "ShowRoom_Mode" 1 "Transport_Mode" 0 "Factory_Mode" ;
VAL_ 688 VDC_PowerMode 15 "Invalid_value" 14 "Reserved" 13 "Reserved" 12 "Reserved" 11 "Reserved" 10 "Reserved" 9 "Reserved" 8 "Reserved" 7 "Reserved" 6 "Driving" 5 "Pre_On" 4 "Standby" 3 "Pre_Off" 2 "Awake" 1 "Sleep" 0 "Deep_Sleep" ;
VAL_ 256 ADV_ErrorSt_EPS 1 "Error" 0 "No Error" ;
VAL_ 256 ADV_AutoParkingModeReq 7 "Reserved" 6 "Reserved" 5 "Reserved" 4 "Reserved" 3 "AVP" 2 "RPA" 1 "APA" 0 "No request" ;
VAL_ 256 ADV_AutoParkingRequestSt 3 "Reserved" 2 "Auto Parking Active" 1 "Auto Parking Request" 0 "No Request" ;
VAL_ 256 APA_DriverInterventionSt 1 "Intervention" 0 "No_Intervention" ;
VAL_ 256 ADV_ErrorSt_APA 3 "Reserved" 2 "Error" 1 "Derate" 0 "Normal" ;
VAL_ 256 ADV_ErrorSt_RPA 3 "Reserved" 2 "Error" 1 "Derate" 0 "Normal" ;
VAL_ 256 ADV_ErrorSt_AVP 3 "Reserved" 2 "Error" 1 "Derate" 0 "Normal" ;
VAL_ 256 ADV_ErrorSt_RVA 3 "Reserved" 2 "Critical Error" 1 "General Error" 0 "No Error" ;
VAL_ 256 ADV_WorkingSt_APA 7 "Reserved" 6 "Reserved" 5 "Reserved" 4 "Exit" 3 "Active" 2 "Available" 1 "Standby" 0 "Off" ;
VAL_ 256 ADV_WorkingSt_RPA 7 "Reserved" 6 "Reserved" 5 "Reserved" 4 "Exit" 3 "Active" 2 "Available" 1 "Standby" 0 "Off" ;
VAL_ 256 ADV_WorkingSt_AVP 7 "Reserved" 6 "Reserved" 5 "Reserved" 4 "Exit" 3 "Active" 2 "Available" 1 "Standby" 0 "Off" ;
VAL_ 256 APA_SecureRequest 1 "Request" 0 "No_Request" ;
VAL_ 256 APA_AutoParkingReq 1 "Request" 0 "No_Request" ;
VAL_ 256 APA_DirectionCmd 3 "Not_Used" 2 "Backward" 1 "Forward" 0 "No_Request" ;
VAL_ 256 ADV_SteeringWheelAngleRequest 32767 "SNA" ;
VAL_ 256 ADV_SteeringWheelAngleSignReques 3 "Reserved" 2 "Right (Negative)" 1 "Left (Positive)" 0 "No Request" ;
VAL_ 256 ADV_SteeringWheelAngleControlReq 3 "Reserved" 2 "Reserved" 1 "EPS control request" 0 "No Request" ;
VAL_ 256 ADV_RearWheelAngleRequestSt 3 "Reserved" 2 "Auto Parking Active" 1 "Auto Parking Request" 0 "No Request" ;
VAL_ 256 ADV_RearWheelAngleRequest 4095 "SNA" ;
VAL_ 256 APA_BrakeFunctionMode 15 "Reserved" 14 "Reserved" 13 "Reserved" 12 "Reserved" 11 "Reserved" 10 "Reserved" 9 "Reserved" 8 "Reserved" 7 "Reserved" 6 "Reserved" 5 "Reserved" 4 "HPA" 3 "AVP(L4)" 2 "RPA(L23)" 1 "APA(L12)" 0 "No_ActIve" ;
VAL_ 256 APA_FailureBrakeMode 7 "Not_Used" 6 "Not_Used" 5 "Not_Used" 4 "Emergency" 3 "Comfort_brake_type_3" 2 "Comfort_brake_type_2" 1 "Comfort_barke_type_1" 0 "Idle_No_Braking" ;
VAL_ 256 APA_EPBLockedRequest 1 "Request" 0 "No_Request" ;
VAL_ 256 APA_EPBRequestEnable 1 "Enable" 0 "Disable" ;
VAL_ 151 HCU_MCU1TMSpeed 65535 "SNA" ;
VAL_ 151 HCU_FrontWheelActTorque 16383 "SNA" ;
VAL_ 151 HCU_FrontWheelActTorqueSt 1 "Failure" 0 "No_failure" ;
VAL_ 151 HCU_FrontWheelMaxDriveTorque 8191 "SNA" ;
VAL_ 151 HCU_FrontWheelMaxDriveTorqueSt 1 "Failure" 0 "No_failure" ;
VAL_ 151 HCU_FrontWheelMaxBrakeRegTorque 8191 "SNA" ;
VAL_ 151 HCU_FrontWheelMaxBrakeRegTorqSt 1 "Failure" 0 "No_failure" ;
VAL_ 151 HCU_FrontWheelBrakeRegTorque 8191 "SNA" ;
VAL_ 151 HCU_FrontWheelBrakeRegTorqueSt 1 "Failure" 0 "No_failure" ;
VAL_ 151 HCU_MCU2TMSpeed 65535 "SNA" ;
VAL_ 151 HCU_RearWheelActTorque 16383 "SNA" ;
VAL_ 151 HCU_RearWheelActTorqueSt 1 "Failure" 0 "No_failure" ;
VAL_ 151 HCU_RearWheelMaxDriveTorque 8191 "SNA" ;
VAL_ 151 HCU_RearWheelMaxDriveTorqueSt 1 "Failure" 0 "No_failure" ;
VAL_ 151 HCU_RearWheelMaxBrakeRegTorque 8191 "SNA" ;
VAL_ 151 HCU_RearWheelMaxBrakeRegTorqSt 1 "Failure" 0 "No_failure" ;
VAL_ 151 HCU_RearWheelBrakeRegTorque 8191 "SNA" ;
VAL_ 151 HCU_RearWheelBrakeRegTorqueSt 1 "Failure" 0 "No_failure" ;
VAL_ 290 HCU2_LeverInfo 7 "Invalid_Value" 6 "Not_Used" 5 "No_connection" 4 "Not_Used" 3 "D" 2 "N" 1 "R" 0 "P" ;
VAL_ 290 HCU_HighVoltageStatus 1 "ON" 0 "OFF" ;
VAL_ 290 HCU_AutoParkingResponse_HPA 1 "Response" 0 "No_response" ;
VAL_ 290 HCU_AutoParkingResponse_AVP 1 "Response" 0 "No_response" ;
VAL_ 290 HCU_AutoParkingResponse_APA 1 "Response" 0 "No_response" ;
VAL_ 290 HCU_AutoParkingResponse_RPA 1 "Response" 0 "No_response" ;
VAL_ 290 HCU_CapabilitySt_AutoParking 3 "Not_Used" 2 "Fault" 1 "Reduced" 0 "Normal" ;
VAL_ 290 HCU_PowertrainErrorSt 1 "Error" 0 "No Error" ;
VAL_ 290 HCU_PowertrainWorkSt 7 "Not_Used_7" 6 "Not_Used_6" 5 "FrontDrive" 4 "RearDrive_to_FourDrive" 3 "FourDrive_to_RearDrive" 2 "AllFourDrive" 1 "RearDrive" 0 "Initiation" ;
VAL_ 290 HCU_MCU1TorqueCtrlAvailableSt 1 "Not Available" 0 "Available" ;
VAL_ 290 HCU_MCU2TorqueCtrlAvailableSt 1 "Not Available" 0 "Available" ;
VAL_ 146 HCU_EPBLeverRequest 7 "Invalid_Value" 6 "Not_Used_5" 5 "Not_Used_4" 4 "Not_Used_3" 3 "D" 2 "N" 1 "R" 0 "P" ;
VAL_ 146 HCU_AccelerationPedalPosition 255 "SNA" ;
VAL_ 146 HCU_CalcAccelerationPedalPositio 255 "SNA" ;
VAL_ 146 HCU_AccelerationPedalOverride 1 "Active" 0 "Inactive" ;
VAL_ 146 HCU_KickdownReq 1 "Active" 0 "Inactive" ;
VAL_ 146 LiveCounter_HCU_2_2 15 "SNA" ;
VAL_ 264 HCU_DriverTorq_FrontWheel 65535 "SNA" ;
VAL_ 264 HCU_AutoDrivingResponseSt_L12 1 "Response" 0 "No_response" ;
VAL_ 264 HCU_AutoDrivingResponseSt_L3 1 "Response" 0 "No_response" ;
VAL_ 264 HCU_CruiseControlSt 3 "Invalid_Value" 2 "Active" 1 "Stand_By" 0 "Inactive" ;
VAL_ 264 HCU_CapabilitySt_AutoDriving 3 "Not_Used" 2 "Fault" 1 "Reduced" 0 "Normal" ;
VAL_ 264 HCU_DriverTorq_RearWheel 65535 "SNA" ;
VAL_ 264 HCU_GradientAccelerationPedal 255 "SNA" ;
VAL_ 147 HCU_SlipContrlIntervention_Front 1 "Intervention" 0 "No Intervention" ;
VAL_ 147 HCU_SlipContrlIntervention_RearA 1 "Intervention" 0 "No Intervention" ;
VAL_ 147 HCU_SlopeContrlIntervention 1 "Intervention" 0 "No Intervention" ;
VAL_ 147 HCU_YawRateContrlIntervention 1 "Intervention" 0 "No Intervention" ;
VAL_ 147 HCU_EVReady 3 "Not_Used" 2 "Enable_Running" 1 "Preparing" 0 "Not_useable" ;
VAL_ 280 VDC_AutoDrivingReq_L12 3 "Not_Used" 2 "L3Request" 1 "L1L2Request" 0 "No_Request" ;
VAL_ 280 VDC_DecelerationReqEnable_AEB 3 "Not_Used" 2 "Request" 1 "Not_Used" 0 "No_Request" ;
VAL_ 280 VDC_SteeringTorqueRequestSign 1 "Right_Negative" 0 "Left_Positive" ;
VAL_ 280 VDC_SteeringTorqueReqSt 1 "Torque_Request" 0 "No_Request" ;
VAL_ 280 VDC_Intervention_LKA 3 "Not_Used" 2 "Right_Intervention" 1 "Left_Intervention" 0 "Not_Intervention" ;
VAL_ 280 VDC_WorkingSt_LKA 3 "Error" 2 "Active" 1 "Standby" 0 "Off" ;
VAL_ 280 VDC_ErrorSt_LKA 1 "Error" 0 "No_Error" ;
VAL_ 280 VDC_AccelerationPedalOverride 1 "Active" 0 "Inactive" ;
VAL_ 280 VDC_WorkingSt_AEB_L12 3 "Not_Used" 2 "Active" 1 "Standby" 0 "Off" ;
VAL_ 280 VDC_ErrorSt_AEB_L12 1 "Error" 0 "No_Error" ;
VAL_ 280 VDC_ErrorSt_ACC_L12 1 "Error" 0 "No_Error" ;
VAL_ 280 VDC_SpeedChangeRequest_L12 2047 "SNA" ;
VAL_ 280 VDC_DriveAwayReq_L12 1 "Request" 0 "No_Request" ;
VAL_ 280 VDC_StopReq_L12 1 "Request" 0 "No_Request" ;
VAL_ 280 VDC_WorkingSt_ACC_L12 7 "Not_Used_3" 6 "Not_Used_2" 5 "Not_Used_1" 4 "Shutoff" 3 "Override" 2 "Active" 1 "Stand_By" 0 "Off" ;
VAL_ 280 VDC_TakeOverTip_LCA 1 "Active" 0 "Inactive" ;
VAL_ 280 VDC_ABPReq_L12 1 "Request" 0 "No_Request" ;
VAL_ 280 VDC_AWBReq_L12 1 "Request" 0 "No_Request" ;
VAL_ 280 VDC_AWBlevel_L12 7 "Not_Used_3" 6 "Not_Used_2" 5 "Not_Used_1" 4 "Level4" 3 "Level3" 2 "Level2" 1 "Level1" 0 "Inactive" ;
VAL_ 280 VDC_CruiseModeFunctionInd 3 "Reserved" 2 "SACC" 1 "ACC" 0 "Off" ;
VAL_ 280 VDC_BrakeModeReq_L12 3 "Not_Used" 2 "Emergency" 1 "Comfortable" 0 "Reserved" ;
VAL_ 280 VDC_DrivedownModeReq_L12 3 "Not_Used" 2 "Immediate_Off" 1 "Fast_Off" 0 "Soft_Off" ;
VAL_ 280 VDC_SecureRequest_L12 1 "Request" 0 "No_Request" ;
VAL_ 280 VDC_AEBSensitivity_L12 3 "High" 2 "Normal" 1 "Low" 0 "Inactive" ;
VAL_ 280 VDC_ErrorSt_LCA 1 "Error" 0 "No_Error" ;
VAL_ 280 VDC_AutoDrivingReq 3 "Not_Used" 2 "L3" 1 "L12" 0 "Inactive" ;
VAL_ 280 VDC_AutoDrivingLevel 3 "Not_Used" 2 "L4" 1 "L3" 0 "L12" ;
VAL_ 280 VDC_HandsOffTip_LCA 3 "Not_Used" 2 "Level2" 1 "Level1" 0 "Inactive" ;
VAL_ 280 VDC_ErrorSt_SACC 3 "Not_Used" 2 "Error" 1 "Derate" 0 "Normal" ;
VAL_ 280 VDC_DecelerationReq_AEB 1023 "SNA" ;
VAL_ 280 VDC_WorkingSt_LCA 7 "Not_Used" 6 "Recoverable-SteeeringOverride" 5 "Recoverable-LaneLineDisappearing" 4 "Exit" 3 "Active" 2 "Available" 1 "Standby" 0 "Off" ;
VAL_ 280 VDC_ErrorSt_VDC 1 "Error" 0 "No_Error" ;
VAL_ 280 VDC_SteeringTorqueRequest 1023 "SNA" ;
VAL_ 280 VDC_AutoDrivingModeReq 7 "Reserved" 6 "Reserved" 5 "L3Backup" 4 "Reserved" 3 "Reserved" 2 "SACC" 1 "LKA" 0 "No_request" ;
VAL_ 280 VDC_WorkingSt_SACC 7 "Reserved" 6 "Reserved" 5 "Reserved" 4 "Exit" 3 "Active" 2 "Available" 1 "Standby" 0 "Off" ;
VAL_ 280 VDC_WorkingSt_DCLC 7 "Reserved" 6 "Reserved" 5 "Reserved" 4 "Exit" 3 "Active" 2 "Available" 1 "Standby" 0 "Off" ;
VAL_ 280 VDC_ErrorSt_EMA 1 "Error" 0 "No_Error" ;
VAL_ 280 VDC_WorkingSt_EMA 7 "Reserved" 6 "Reserved" 5 "Reserved" 4 "Exit" 3 "Active" 2 "Available" 1 "Standby" 0 "Off" ;
VAL_ 280 VDC_SteeringWheelAngleRequest 32767 "SNA" ;
VAL_ 280 SACC_RearWheelAngleRequestSt 1 "Valid" 0 "Invalid" ;
VAL_ 280 VDC_SteeringWheelAngleSignReques 3 "Reserved" 2 "Right (Negative)" 1 "Left (Positive)" 0 "No Request" ;
VAL_ 280 VDC_SteeringWheelAngleControlReq 3 "Reserved" 2 "Reserved" 1 "EPS control request" 0 "No Request" ;
VAL_ 280 SACC_RearWheelReturnReq 1 "Valid" 0 "Invalid" ;
VAL_ 280 LKA_RearWheelAngleRequestSt 1 "Valid" 0 "Invalid" ;
VAL_ 280 LKA_RearWheelReturnReq 1 "Valid" 0 "Invalid" ;
VAL_ 280 VDC_AutoDrivingModeReq_EMA 1 "Request" 0 "No request" ;
VAL_ 280 VDC_SteeringWheelBlendingGain 255 "SNA" ;
VAL_ 280 VDC_SteeringMaxTorqueRequest 1023 "SNA" ;
VAL_ 280 SACC_RearWheelAngleRequest 4095 "SNA" ;
VAL_ 280 LKA_RearWheelAngleRequest 4095 "SNA" ;
VAL_ 280 VDC_WorkingSt_FCW 3 "Not_Used" 2 "Active" 1 "Standby" 0 "Off" ;
VAL_ 280 VDC_ErrorSt_FCW 1 "Error" 0 "No_Error" ;
VAL_ 282 HAD_AutoDrivingReq_L3 3 "Not_Used" 2 "L3Request" 1 "L1L2Request" 0 "No_Request" ;
VAL_ 282 HAD_SpeedChangeRequest_L3 2047 "SNA" ;
VAL_ 282 HAD_TimeGapSetting 7 "Reserved" 6 "Reserved" 5 "Reserved" 4 "Reserved" 3 "TimeGap4" 2 "TimeGap3" 1 "TimeGap2" 0 "TimeGap1" ;
VAL_ 282 NOP_RearWheelAngleRequest 4095 "SNA" ;
VAL_ 282 NOP_RearWheelAngleRequestSt 1 "Valid" 0 "Invalid" ;
VAL_ 282 NOP_RearWheelReturnReq 1 "Valid" 0 "Invalid" ;
VAL_ 282 HAD_ObjectDetection 1 "Target_object_detected" 0 "No_object" ;
VAL_ 282 HAD_TakeOverReq 1 "Request" 0 "No_request" ;
VAL_ 282 HAD_CruiseSpeedSetting_ACC 255 "SNA" ;
VAL_ 282 HAD_SysTextinfo 15 "Radar_is_covered" 14 "Radar_not_calibration" 13 "SACC_cancelled_autoly" 12 "LCA_cancelled_autoly" 11 "ACC_cancelled_autoly" 10 "Speed_is_less_than_10,unable_to_active_ACC" 9 "Camera_is_not_calibration" 8 "Camera_is_polluted,_please_clean_the_camera_cover." 7 "System_initial" 6 "Bad_weather,system_can_not_work" 5 "Because__driver_cancel_operation" 4 "Because_ESC_interven,_ACC_cancelled" 3 "Stop-Go_clue_-step_gas_pedal_or_press_resume_key" 2 "Radar_error" 1 "Conditions_not_satisfied,_unable_to_active_ACC" 0 "No_display" ;
VAL_ 282 HAD_LDWModeInd 3 "Not_Used" 2 "LDW+LKA" 1 "LDW+Vibration" 0 "LDW_only" ;
VAL_ 282 HAD_AutoLightModeReq 1 "Request" 0 "No_request" ;
VAL_ 282 HAD_HazardWarningLampRequest 1 "Request" 0 "No_request" ;
VAL_ 282 HAD_WorkingSt_LDW 3 "Error" 2 "Active" 1 "Standby" 0 "Off" ;
VAL_ 282 HAD_WarningCmd_LDW 3 "Not_Used" 2 "RightWarning" 1 "LeftWarning" 0 "Inactive" ;
VAL_ 282 HAD_LDWLaneDetectSt 3 "Both_side_lane_marks_detected" 2 "Right_side_lane_mark_detected" 1 "Left_side_lane_mark_detected" 0 "Neither_side_lane_mark_detected" ;
VAL_ 282 HAD_SensitivityInd_LDW 3 "Not_Used" 2 "High" 1 "Normal" 0 "Low" ;
VAL_ 282 HAD_ErrorSt_LDW 1 "Error" 0 "No_Error" ;
VAL_ 282 HAD_WorkingSt_FCW 3 "Not_Used" 2 "Active" 1 "Standby" 0 "Off" ;
VAL_ 282 HAD_DriveAwayReq_L3 1 "Request" 0 "No_Request" ;
VAL_ 282 HAD_StopReq_L3 1 "Request" 0 "No_Request" ;
VAL_ 282 HAD_AccelerationPedalOverride 1 "Active" 0 "Inactive" ;
VAL_ 282 HAD_SensitivityInd_FCW 3 "Not_Used" 2 "High" 1 "Normal" 0 "Low" ;
VAL_ 282 HAD_FCWModeInd 3 "Not_Used" 2 "FCW+EAB" 1 "Not_Used" 0 "FCW_only" ;
VAL_ 282 HAD_WiperAutoLeverReq 1 "Request" 0 "No_request" ;
VAL_ 282 HAD_VASFunctionInd 1 "On" 0 "Off" ;
VAL_ 282 HAD_SACCNotSatisfiedCondition 7 "Abnormal_exited_for_driver_not_taking_over,power_on_again_and_try_then" 6 "AutoParking_active" 5 "The_door_is_open" 4 "Hands_off_" 3 "Turning_around" 2 "Tite_your_seatbelt" 1 "Speed_too_high" 0 "Inactive" ;
VAL_ 282 HAD_LDW_SpeechControlFeedback 7 "Reserved" 6 "Reserved" 5 "Reserved" 4 "On_Failure" 3 "On_Success" 2 "Off_Failure" 1 "Off_Success" 0 "Inactive" ;
VAL_ 282 HAD_IFCSystemError 3 "Not_Used" 2 "Camera_is_covered,please_clean" 1 "System_error" 0 "No_error" ;
VAL_ 282 HAD_IFCCalibrationStatus 3 "Not_Calibrationed" 2 "Calibration_Failed" 1 "Calibrating" 0 "Calibration_Success" ;
VAL_ 282 HAD_WarningCmd_VAS 1 "Active" 0 "Inactive" ;
VAL_ 282 HAD_LeftTurningLampRequest 3 "Not_Used" 2 "On" 1 "Off" 0 "No_request" ;
VAL_ 282 HAD_RightTurningLampRequest 3 "Not_Used" 2 "On" 1 "Off" 0 "No_request" ;
VAL_ 282 HAD_ValetModeStatus 1 "On" 0 "Off" ;
VAL_ 282 HAD_BrakeModeReq_L3 3 "Not_Used" 2 "Emergency" 1 "Comfortable" 0 "Not_Used" ;
VAL_ 282 HAD_DrivedownModeReq_L3 3 "Not_Used" 2 "Immediate_Off" 1 "Fast_Off" 0 "Soft_Off" ;
VAL_ 282 HAD_SecureRequest_L3 3 "Not_Used" 2 "Not_Used" 1 "Secure_request" 0 "No_request" ;
VAL_ 282 HAD_ErrorSt_AutoDriving_L3 1 "Error" 0 "No_Error" ;
VAL_ 282 HAD_WorkingSt_NOP 7 "Reserved" 6 "Reserved" 5 "Reserved" 4 "Exit" 3 "Active" 2 "Available" 1 "Standby" 0 "Off" ;
VAL_ 282 HAD_ErrorSt_NOP 3 "Not_Used" 2 "Error" 1 "Derate" 0 "Normal" ;
VAL_ 282 HAD_ErrorSt_HAD 1 "Error" 0 "No_Error" ;
VAL_ 282 HAD_AutoDrivingModeReq_NOP 1 "Request" 0 "No_Request" ;
VAL_ 282 HAD_AutoDrivingModeReq_NGP 1 "Request" 0 "No_Request" ;
VAL_ 282 HAD_SteeringWheelBlendingGain 255 "SNA" ;
VAL_ 282 HAD_SteeringWheelAngleRequest 32767 "SNA" ;
VAL_ 282 HAD_SteeringWheelAngleSignReques 3 "Reserved" 2 "Right (Negative)" 1 "Left (Positive)" 0 "No Request" ;
VAL_ 282 HAD_SteeringWheelAngleControlReq 3 "Reserved" 2 "Reserved" 1 "EPS control request" 0 "No Request" ;
VAL_ 282 HAD_WorkingSt_NGP 7 "Reserved" 6 "Reserved" 5 "Reserved" 4 "Exit" 3 "Active" 2 "Available" 1 "Standby" 0 "Off" ;
VAL_ 282 HAD_ErrorSt_NGP 3 "Not_Used" 2 "Error" 1 "Derate" 0 "Normal" ;
VAL_ 512 CrashInfo 1 "Crash" 0 "No Crash" ;
VAL_ 512 SysSt_ACU 3 "Reserved" 2 "Factory mode" 1 "Error" 0 "No error" ;
VAL_ 586 DoorSt_FL 1 "Open" 0 "Close" ;
VAL_ 580 SeatBeltSt_DSCU 3 "Reserved" 2 "Reserved" 1 "Buckled" 0 "Unbuckled" ;
VAL_ 288 EGSM_ParkButton 1 "Pressed" 0 "Not pressed" ;
VAL_ 308 YawRate 4095 "SNA" ;
VAL_ 308 YRSSt 1 "Not Calibrated" 0 "Calibrated" ;
VAL_ 308 Acceleration_X 2047 "SNA" ;
VAL_ 308 Acceleration_Y 2047 "SNA" ;
VAL_ 308 ErrorSt_YRS 1 "Error" 0 "No Error" ;
VAL_ 588 DoorSt_FR 1 "Open" 0 "Close" ;
VAL_ 292 Acceleration_X_ACU 4095 "SNA" ;
VAL_ 292 Acceleration_Y_ACU 4095 "SNA" ;
VAL_ 292 YawRate_ACU 65535 "SNA" ;
VAL_ 292 LatSensorSt 3 "Initializing" 2 "Not_Used" 1 "Valid" 0 "Invalid" ;
VAL_ 292 LgtSensorSt 3 "Initializing" 2 "Not_Used" 1 "Valid" 0 "Invalid" ;
VAL_ 292 YRSCalibrateSt_ACU 1 "Calibrated" 0 "Not_Calibrated" ;
VAL_ 292 YRSSt_ACU 3 "Initializing" 2 "Not_Used" 1 "Valid" 0 "Invalid" ;
VAL_ 640 EPBFunctionSet 3 "Reserved" 2 "Lock" 1 "Release" 0 "Inactive" ;
